VERSION "ADD"

NS_ :

BS_:

BU_: ADD

BO_ 379 ADD_ChassisFusion_0x17B: 16 ADD
 SG_ ADDKeepAwakeReq : 39|1@0+ (1,0) [0|1] "" Vector__XXX
 SG_ ParkGearReqEnaFrmADD : 20|2@0+ (1,0) [0|3] "" Vector__XXX
 SG_ ParkGearReqFrmADD : 18|3@0+ (1,0) [0|7] "" Vector__XXX
 SG_ ParkGearReqSigGrpChks : 7|8@0+ (1,0) [0|255] "" Vector__XXX
 SG_ ParkGearReqSigGrpCntr : 11|4@0+ (1,0) [0|15] "" Vector__XXX
 SG_ ParkGearReqSigGrpFV : 87|16@0+ (1,0) [0|65535] "" Vector__XXX
 SG_ ParkGearReqSigGrpMAC : 103|32@0+ (1,0) [0|0] "" Vector__XXX
 SG_ RPAHVOnReqFrmADD : 21|1@0+ (1,0) [0|1] "" Vector__XXX
 SG_ RPAPrkinRecdFrmADD : 23|2@0+ (1,0) [0|3] "" Vector__XXX

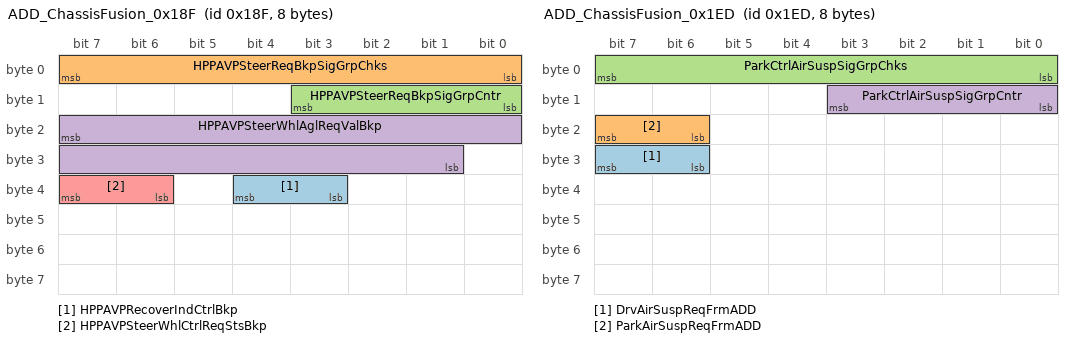
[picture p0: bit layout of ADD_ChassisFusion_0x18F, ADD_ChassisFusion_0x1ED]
BO_ 399 ADD_ChassisFusion_0x18F: 8 ADD
 SG_ HPPAVPRecoverIndCtrlBkp : 36|2@0+ (1,0) [0|3] "" Vector__XXX
 SG_ HPPAVPSteerReqBkpSigGrpChks : 7|8@0+ (1,0) [0|255] "" Vector__XXX
 SG_ HPPAVPSteerReqBkpSigGrpCntr : 11|4@0+ (1,0) [0|15] "" Vector__XXX
 SG_ HPPAVPSteerWhlAglReqValBkp : 23|15@0- (0.0625,0) [-780|780] "deg" Vector__XXX
 SG_ HPPAVPSteerWhlCtrlReqStsBkp : 39|2@0+ (1,0) [0|3] "" Vector__XXX

BO_ 493 ADD_ChassisFusion_0x1ED: 8 ADD
 SG_ DrvAirSuspReqFrmADD : 31|2@0+ (1,0) [0|3] "" Vector__XXX
 SG_ ParkAirSuspReqFrmADD : 23|2@0+ (1,0) [0|3] "" Vector__XXX
 SG_ ParkCtrlAirSuspSigGrpChks : 7|8@0+ (1,0) [0|255] "" Vector__XXX
 SG_ ParkCtrlAirSuspSigGrpCntr : 11|4@0+ (1,0) [0|15] "" Vector__XXX

BO_ 512 ADD_ChassisFusion_0x200: 48 ADD
 SG_ ADDBSDLCAStsFrmADD : 271|2@0+ (1,0) [0|3] "" Vector__XXX
 SG_ ADSAEBStsFrmADD : 279|3@0+ (1,0) [0|7] "" Vector__XXX
 SG_ ADSAEBTarDirFrmADD : 303|3@0+ (1,0) [0|4] "" Vector__XXX
 SG_ ADSAEBWarnReqFrmADD : 37|2@0+ (1,0) [0|3] "" Vector__XXX
 SG_ AdsAutoTurnLiCnclReqFrmADD : 89|2@0+ (1,0) [0|3] "" Vector__XXX
 SG_ AdsAutoTurnLiSwtStsFrmADD : 167|3@0+ (1,0) [0|7] "" Vector__XXX
 SG_ AdsAutoTurnLiUnavlRsnFrmADD : 164|4@0+ (1,0) [0|15] "" Vector__XXX
 SG_ ADSBSDLCAAudioWarnReqFrmADD : 79|2@0+ (1,0) [0|2] "" Vector__XXX
 SG_ ADSBSDLCAWarnReqLeFrmADD : 35|2@0+ (1,0) [0|3] "" Vector__XXX
 SG_ ADSBSDLCAWarnReqRiFrmADD : 47|2@0+ (1,0) [0|3] "" Vector__XXX
 SG_ ADSBSDLightWarningLeReqFrmADD : 77|2@0+ (1,0) [0|2] "" Vector__XXX
 SG_ ADSBSDLightWarningRiReqFrmADD : 75|2@0+ (1,0) [0|2] "" Vector__XXX
 SG_ ADSDOWStsFrmADD : 269|2@0+ (1,0) [0|3] "" Vector__XXX
 SG_ ADSDOWWarnReqFrLeFrmADD : 45|2@0+ (1,0) [0|3] "" Vector__XXX
 SG_ ADSDOWWarnReqFrRiFrmADD : 15|2@0+ (1,0) [0|3] "" Vector__XXX
 SG_ ADSDOWWarnReqReLeFrmADD : 13|2@0+ (1,0) [0|3] "" Vector__XXX
 SG_ ADSDOWWarnReqReRiFrmADD : 43|2@0+ (1,0) [0|3] "" Vector__XXX
 SG_ ADSELKStsFrmADD : 276|3@0+ (1,0) [0|7] "" Vector__XXX
 SG_ ADSESSStsFrmADD : 287|3@0+ (1,0) [0|7] "" Vector__XXX
 SG_ ADSESSWarnReqFrmADD : 41|1@0+ (1,0) [0|1] "" Vector__XXX
 SG_ ADSFctStsSigGrpChks : 263|8@0+ (1,0) [0|255] "" Vector__XXX
 SG_ ADSFctStsSigGrpCntr : 267|4@0+ (1,0) [0|15] "" Vector__XXX
 SG_ ADSFCWReqFrmADD : 23|2@0+ (1,0) [0|3] "" Vector__XXX
 SG_ ADSFCWStsFrmADD : 284|3@0+ (1,0) [0|7] "" Vector__XXX
 SG_ ADSGearReqSigGrpChks : 175|8@0+ (1,0) [0|255] "" Vector__XXX
 SG_ ADSGearReqSigGrpCntr : 179|4@0+ (1,0) [0|15] "" Vector__XXX
 SG_ AdsIntelgntSpdSwtStsFrmADD : 159|3@0+ (1,0) [0|7] "" Vector__XXX
 SG_ AdsIntelgntSpdUnavlRsnFrmADD : 156|3@0+ (1,0) [0|7] "" Vector__XXX
 SG_ ADSLDPHandOffExitFrmADD : 56|1@0+ (1,0) [0|1] "" Vector__XXX
 SG_ ADSLDPHandOffWarningFrmADD : 65|2@0+ (1,0) [0|3] "" Vector__XXX
 SG_ ADSLDPStsFrmADD : 295|3@0+ (1,0) [0|7] "" Vector__XXX
 SG_ ADSLDPWarnReqLeFrmADD : 21|1@0+ (1,0) [0|1] "" Vector__XXX
 SG_ ADSLDPWarnReqRiFrmADD : 20|1@0+ (1,0) [0|1] "" Vector__XXX
 SG_ ADSLDWStsFrmADD : 292|3@0+ (1,0) [0|7] "" Vector__XXX
 SG_ ADSLDWWarnLeReqFrmADD : 19|1@0+ (1,0) [0|1] "" Vector__XXX
 SG_ ADSLDWWarnRiReqFrmADD : 18|1@0+ (1,0) [0|1] "" Vector__XXX
 SG_ AdsLearnSwtStsFrmADD : 370|3@0+ (1,0) [0|7] "" Vector__XXX
 SG_ AdsLearnSwtUnavlRsnFrmADD : 363|4@0+ (1,0) [0|15] "" Vector__XXX
 SG_ ADSLiReqFrmADD : 142|2@0+ (1,0) [0|3] "" Vector__XXX
 SG_ ADSMAIInhibitReqFrmADD : 207|2@0+ (1,0) [0|3] "" Vector__XXX
 SG_ ADSMAIStsFrmADD : 205|3@0+ (1,0) [0|7] "" Vector__XXX
 SG_ ADSMAIWarnReqFrmADD : 202|2@0+ (1,0) [0|3] "" Vector__XXX
 SG_ AdsModSwtStsFrmADD : 367|4@0+ (1,0) [0|15] "" Vector__XXX
 SG_ AdsNOAOddSwtStsFrmADD : 355|4@0+ (1,0) [0|15] "" Vector__XXX
 SG_ AdsNOAOddSwtUnavlRsnFrmADD : 373|3@0+ (1,0) [0|7] "" Vector__XXX
 SG_ ADSRCTAStsFrmADD : 273|2@0+ (1,0) [0|3] "" Vector__XXX
 SG_ ADSRCTAWarnReqLeFrmADD : 17|2@0+ (1,0) [0|3] "" Vector__XXX
 SG_ ADSRCTAWarnReqRiFrmADD : 31|2@0+ (1,0) [0|3] "" Vector__XXX
 SG_ ADSRCTBStsFrmADD : 281|2@0+ (1,0) [0|3] "" Vector__XXX
 SG_ ADSRCTBWarnReqLeFrmADD : 29|2@0+ (1,0) [0|3] "" Vector__XXX
 SG_ ADSRCTBWarnReqRiFrmADD : 27|2@0+ (1,0) [0|3] "" Vector__XXX
 SG_ ADSRCWStsFrmADD : 289|2@0+ (1,0) [0|3] "" Vector__XXX
 SG_ ADSRCWWarnReqFrmADD : 25|2@0+ (1,0) [0|3] "" Vector__XXX
 SG_ ADSSysErrorRmdFrmADD : 95|2@0+ (1,0) [0|3] "" Vector__XXX
 SG_ ADSSysErrorStsFrmADD : 93|2@0+ (1,0) [0|3] "" Vector__XXX
 SG_ ADSTakeoverRmdFrmADD : 91|2@0+ (1,0) [0|3] "" Vector__XXX
 SG_ ADSTLAStsFrmADD : 335|3@0+ (1,0) [0|7] "" Vector__XXX
 SG_ AdsTrfcLiCtrlSwtStsFrmADD : 375|2@0+ (1,0) [0|3] "" Vector__XXX
 SG_ ADSVcCtrlArbFrmADD : 39|2@0+ (1,0) [0|3] "" Vector__XXX
 SG_ AdsVehDetourSwtStsFrmADD : 357|2@0+ (1,0) [0|3] "" Vector__XXX
 SG_ ADSWarnSigGrpChks : 7|8@0+ (1,0) [0|255] "" Vector__XXX
 SG_ ADSWarnSigGrpCntr : 11|4@0+ (1,0) [0|15] "" Vector__XXX
 SG_ ADSwtStsSigGrp2Chks : 343|8@0+ (1,0) [0|255] "" Vector__XXX
 SG_ ADSwtStsSigGrp2Cntr : 347|4@0+ (1,0) [0|15] "" Vector__XXX
 SG_ AEBTarObjClassFrmADD : 223|2@0+ (1,0) [0|3] "" Vector__XXX
 SG_ AEBTarObjTTIFrmADD : 231|8@0+ (0.02,0) [0|5.1] "" Vector__XXX
 SG_ AEBtoIDPFrmADDChks : 215|8@0+ (1,0) [0|255] "" Vector__XXX
 SG_ AEBtoIDPFrmADDCntr : 219|4@0+ (1,0) [0|15] "" Vector__XXX
 SG_ AutoDrvLaneChgStsFrmADD : 103|4@0+ (1,0) [0|15] "" Vector__XXX
 SG_ AVMCamVideoChainSts : 245|2@0+ (1,0) [0|3] "" Vector__XXX
 SG_ AVMCamVideoChainStsChks : 239|8@0+ (1,0) [0|255] "" Vector__XXX
 SG_ AVMCamVideoChainStsCntr : 243|4@0+ (1,0) [0|15] "" Vector__XXX
 SG_ DrvAtmLiReqFrmADD : 40|1@0+ (1,0) [0|1] "" Vector__XXX
 SG_ DrvGearReqFrmADD : 191|3@0+ (1,0) [0|7] "" Vector__XXX
 SG_ DrvGearReqVldFrmADD : 188|1@0+ (1,0) [0|1] "" Vector__XXX
 SG_ DrvHUDDspFrmADD : 99|4@0+ (1,0) [0|15] "" Vector__XXX
 SG_ DrvLaneChgStsFrmADD : 111|4@0+ (1,0) [0|15] "" Vector__XXX
 SG_ DrvMdlStsFrmADD : 317|3@0+ (1,0) [0|7] "" Vector__XXX
 SG_ DrvNOAExtLgtDstFrmADD : 119|9@0+ (1,0) [0|511] "m" Vector__XXX
 SG_ DrvNOAQutLgtDstFrmADD : 135|9@0+ (1,0) [0|511] "m" Vector__XXX
 SG_ DrvNOARemdFrmADD : 327|6@0+ (1,0) [0|63] "" Vector__XXX
 SG_ DrvPltSysStsFrmADD : 126|4@0+ (1,0) [0|15] "" Vector__XXX
 SG_ DrvPnt2PntExtLgtDstFrmADD : 311|9@0+ (1,0) [0|511] "m" Vector__XXX
 SG_ DrvPnt2PntSysStsFrmADD : 332|5@0+ (1,0) [0|31] "" Vector__XXX
 SG_ DrvrSeldDstLvlFrmADD : 122|3@0+ (1,0) [0|7] "" Vector__XXX
 SG_ DrvSysWarnFrmADD : 55|3@0+ (1,0) [0|7] "" Vector__XXX
 SG_ DrvTurnLiReqFrmADD : 140|2@0+ (1,0) [0|3] "" Vector__XXX
 SG_ IndcrCancelReqFrmADD : 138|2@0+ (1,0) [0|3] "" Vector__XXX
 SG_ LidarCleanReqFrmADD : 321|2@0+ (1,0) [0|3] "" Vector__XXX
 SG_ NOASysStsFrmADD : 107|4@0+ (1,0) [0|15] "" Vector__XXX
 SG_ NOATypFrmADD : 153|2@0+ (1,0) [0|3] "-" Vector__XXX
 SG_ TSASignQlyFrmADD : 63|7@0+ (1,0) [0|126] "" Vector__XXX
 SG_ TSASignTypeFrmADD : 71|6@0+ (1,0) [0|63] "" Vector__XXX
 SG_ TSASpdLimitFrmADD : 52|5@0+ (1,0) [0|31] "" Vector__XXX
 SG_ TSASpdLimitUnitFrmADD : 33|2@0+ (1,0) [0|3] "" Vector__XXX
 SG_ UserFbReqFrmADD : 151|2@0+ (1,0) [0|3] "" Vector__XXX

BO_ 513 ADD_ChassisFusion_0x201: 48 ADD
 SG_ ADSAPPUnableOpenRsnFrmADD : 162|3@0+ (1,0) [0|7] "" Vector__XXX
 SG_ ADSAVPStsFrmADD : 127|4@0+ (1,0) [0|15] "" Vector__XXX
 SG_ ADSHPPStsFrmADD : 95|4@0+ (1,0) [0|15] "" Vector__XXX
 SG_ ADSLRRSnsrStsFrmADD : 351|4@0+ (1,0) [0|15] "" Vector__XXX
 SG_ ADSRLSRSnsrStsFrmADD : 71|4@0+ (1,0) [0|15] "" Vector__XXX
 SG_ ADSRRSRSnsrStsFrmADD : 67|4@0+ (1,0) [0|15] "" Vector__XXX
 SG_ AFrCamStsFrmADD : 245|3@0+ (1,0) [0|7] "" Vector__XXX
 SG_ ALeCamStsFrmADD : 250|3@0+ (1,0) [0|7] "" Vector__XXX
 SG_ APAIcnDispStsFrmADD : 335|3@0+ (1,0) [0|7] "" Vector__XXX
 SG_ APAVcFbFrmADD : 231|7@0+ (1,0) [0|127] "" Vector__XXX
 SG_ APAVcQuitAvlFrmADD : 220|1@0+ (1,0) [0|1] "" Vector__XXX
 SG_ APAVcStsFrmADD : 219|1@0+ (1,0) [0|1] "" Vector__XXX
 SG_ AReCamStsFrmADD : 253|3@0+ (1,0) [0|7] "" Vector__XXX
 SG_ ARiCamStsFrmADD : 7|3@0+ (1,0) [0|7] "" Vector__XXX
 SG_ AVMOpnReqFrmADD : 223|3@0+ (1,0) [0|7] "" Vector__XXX
 SG_ AVPHPPStatusSigGrpChks : 87|8@0+ (1,0) [0|255] "" Vector__XXX
 SG_ AVPHPPStatusSigGrpCntr : 91|4@0+ (1,0) [0|15] "" Vector__XXX
 SG_ AVPIcnDispStsFrmADD : 332|3@0+ (1,0) [0|7] "" Vector__XXX
 SG_ CameraStsforADBFrmADD : 279|2@0+ (1,0) [0|3] "" Vector__XXX
 SG_ CameraStsFrmADD : 277|2@0+ (1,0) [0|3] "" Vector__XXX
 SG_ F120CamStsFrmADD : 35|3@0+ (1,0) [0|7] "" Vector__XXX
 SG_ F120DVRStsFrmADD : 15|3@0+ (1,0) [0|7] "" Vector__XXX
 SG_ F30CamStsFrmADD : 4|3@0+ (1,0) [0|7] "" Vector__XXX
 SG_ F30DVRStsFrmADD : 12|3@0+ (1,0) [0|7] "" Vector__XXX
 SG_ FLidarStsFrmADD : 47|4@0+ (1,0) [0|15] "" Vector__XXX
 SG_ FUSSStsFrmADD : 43|4@0+ (1,0) [0|15] "" Vector__XXX
 SG_ HPPActiveSubStsFrmADD : 114|3@0+ (1,0) [0|7] "" Vector__XXX
 SG_ HPPAlrtWarnFrmADD : 151|3@0+ (1,0) [0|7] "" Vector__XXX
 SG_ HPPAVPModSts : 76|3@0+ (1,0) [0|7] "" Vector__XXX
 SG_ HPPBakMapDfltParkSlotDispFrmADD : 311|1@0+ (1,0) [0|1] "" Vector__XXX
 SG_ HPPDriverOperateDialogFrmADD : 111|4@0+ (1,0) [0|15] "" Vector__XXX
 SG_ HPPDriverOperateInd2FrmADD : 119|5@0+ (1,0) [0|31] "" Vector__XXX
 SG_ HPPDriverOperateIndFrmADD : 143|5@0+ (1,0) [0|31] "" Vector__XXX
 SG_ HPPIcnDispStsFrmADD : 343|3@0+ (1,0) [0|7] "" Vector__XXX
 SG_ HPPInfotipFrmADD : 103|6@0+ (1,0) [0|63] "" Vector__XXX
 SG_ HPPLearnSubStsFrmADD : 123|4@0+ (1,0) [0|15] "" Vector__XXX
 SG_ HPPLrnVcFbFrmADD : 218|1@0+ (1,0) [0|1] "" Vector__XXX
 SG_ HPPPlayBackPushFrmADD : 310|1@0+ (1,0) [0|1] "" Vector__XXX
 SG_ HPPQuitIndFrmADD : 159|7@0+ (1,0) [0|127] "" Vector__XXX
 SG_ HPPRecoverButtonStsFrmADD : 307|2@0+ (1,0) [0|3] "" Vector__XXX
 SG_ HPPRecoverIndFrmADD : 167|5@0+ (1,0) [0|31] "" Vector__XXX
 SG_ HPPRouteInd2FrmADD : 107|4@0+ (1,0) [0|15] "" Vector__XXX
 SG_ HPPRouteIndFrmADD : 148|5@0+ (1,0) [0|31] "" Vector__XXX
 SG_ HPPRouteManageStsFrmADD : 309|1@0+ (1,0) [0|1] "" Vector__XXX
 SG_ HPPToSRSigGrpChks : 295|8@0+ (1,0) [0|255] "" Vector__XXX
 SG_ HPPToSRSigGrpCntr : 299|4@0+ (1,0) [0|15] "" Vector__XXX
 SG_ HPPUnableToActiveIndFrmADD : 135|7@0+ (1,0) [0|127] "" Vector__XXX
 SG_ HPPVehInParkSlotFrmADD : 308|1@0+ (1,0) [0|1] "" Vector__XXX
 SG_ IMUStsFrmADD : 55|4@0+ (1,0) [0|15] "" Vector__XXX
 SG_ ISPLigtSnsrVFrmADD : 263|16@0+ (1,0) [0|65535] "Lux" Vector__XXX
 SG_ LidarStsFrmADD : 275|2@0+ (1,0) [0|3] "" Vector__XXX
 SG_ ParkIcnStsSigGrpChks : 319|8@0+ (1,0) [0|255] "" Vector__XXX
 SG_ ParkIcnStsSigGrpCntr : 323|4@0+ (1,0) [0|15] "" Vector__XXX
 SG_ ParkVCstatusSigGrpChks : 207|8@0+ (1,0) [0|255] "" Vector__XXX
 SG_ ParkVCstatusSigGrpCntr : 211|4@0+ (1,0) [0|15] "" Vector__XXX
 SG_ ParkVicShdFrmADD : 215|3@0+ (1,0) [0|7] "" Vector__XXX
 SG_ PrkSteerWhlBtnLi : 329|2@0+ (1,0) [0|3] "" Vector__XXX
 SG_ ReCamStsFrmADD : 287|3@0+ (1,0) [0|7] "" Vector__XXX
 SG_ ReDVRStsFrmADD : 39|3@0+ (1,0) [0|7] "" Vector__XXX
 SG_ RUSSStsFrmADD : 51|4@0+ (1,0) [0|15] "" Vector__XXX
 SG_ SLFCamStsFrmADD : 234|3@0+ (1,0) [0|7] "" Vector__XXX
 SG_ SLFDVRStsFrmADD : 23|3@0+ (1,0) [0|7] "" Vector__XXX
 SG_ SLLidarStsFrmADD : 63|4@0+ (1,0) [0|15] "" Vector__XXX
 SG_ SLRCamStsFrmADD : 237|3@0+ (1,0) [0|7] "" Vector__XXX
 SG_ SLRDVRStsFrmADD : 20|3@0+ (1,0) [0|7] "" Vector__XXX
 SG_ SnmDetInfoFrmADD : 175|16@0+ (1,0) [0|65535] "" Vector__XXX
 SG_ SnmDetResFrmADD : 185|2@0+ (1,0) [0|3] "" Vector__XXX
 SG_ SnmF120CamDetResFrmADD : 187|2@0+ (1,0) [0|3] "" Vector__XXX
 SG_ SnmReCamDetResFrmADD : 189|2@0+ (1,0) [0|3] "" Vector__XXX
 SG_ SnmSLFCamDetResFrmADD : 191|2@0+ (1,0) [0|3] "" Vector__XXX
 SG_ SnmSLRCamDetResFrmADD : 193|2@0+ (1,0) [0|3] "" Vector__XXX
 SG_ SnmSRFCamDetResFrmADD : 195|2@0+ (1,0) [0|3] "" Vector__XXX
 SG_ SnmSRRCamDetResFrmADD : 197|2@0+ (1,0) [0|3] "" Vector__XXX
 SG_ SRFCamStsFrmADD : 242|3@0+ (1,0) [0|7] "" Vector__XXX
 SG_ SRFDVRStsFrmADD : 31|3@0+ (1,0) [0|7] "" Vector__XXX
 SG_ SRLidarStsFrmADD : 59|4@0+ (1,0) [0|15] "" Vector__XXX
 SG_ SRRCamStsFrmADD : 79|3@0+ (1,0) [0|7] "" Vector__XXX
 SG_ SRRDVRStsFrmADD : 28|3@0+ (1,0) [0|7] "" Vector__XXX

BO_ 516 ADD_ChassisFusion_0x204: 32 ADD
 SG_ APAAlrtWarnFrmADD : 121|2@0+ (1,0) [0|3] "" Vector__XXX
 SG_ APAButtonReqFrmADD : 199|2@0+ (1,0) [0|3] "" Vector__XXX
 SG_ APARPAActiveSubFunFrmADD : 114|3@0+ (1,0) [0|7] "" Vector__XXX
 SG_ APARPADriverOperateInd2FrmADD : 159|6@0+ (1,0) [0|63] "" Vector__XXX
 SG_ APARPADriverOperateIndFrmADD : 127|6@0+ (1,0) [0|63] "" Vector__XXX
 SG_ APARPAQuitReasonIndFrmADD : 135|6@0+ (1,0) [0|63] "" Vector__XXX
 SG_ APARPARecoverIndFrmADD : 143|5@0+ (1,0) [0|31] "" Vector__XXX
 SG_ APARPAstatusFrmADD : 118|4@0+ (1,0) [0|15] "" Vector__XXX
 SG_ APARPAstatusSigGrpChks : 87|8@0+ (1,0) [0|255] "" Vector__XXX
 SG_ APARPAstatusSigGrpCntr : 91|4@0+ (1,0) [0|15] "" Vector__XXX
 SG_ APARPAUnableToActiveIndFrmADD : 151|6@0+ (1,0) [0|63] "" Vector__XXX
 SG_ AVPCharLidCtrlFrmADD : 15|2@0+ (1,0) [0|3] "" Vector__XXX
 SG_ DriverlessStsFrmADD : 185|2@0+ (1,0) [0|3] "" Vector__XXX
 SG_ OutdoorPrkDrvrOperIndFrmADD : 197|6@0+ (1,0) [0|63] "" Vector__XXX
 SG_ OutdoorPrkQuitIndFrmADD : 191|6@0+ (1,0) [0|63] "" Vector__XXX
 SG_ OutdoorPrkRecoverIndFrmADD : 183|5@0+ (1,0) [0|31] "" Vector__XXX
 SG_ OutdoorPrkUnableToActvIndFrmADD : 175|6@0+ (1,0) [0|63] "" Vector__XXX
 SG_ ParkActiveRearSpoilerReqFrmADD : 202|3@0+ (1,0) [0|7] "" Vector__XXX
 SG_ ParkAtmLiReqFrmADD : 13|2@0+ (1,0) [0|3] "" Vector__XXX
 SG_ ParkBackMirrorUnfoldReqFrmADD : 23|2@0+ (1,0) [0|3] "" Vector__XXX
 SG_ ParkCornrLiReqFrmADD : 207|2@0+ (1,0) [0|3] "" Vector__XXX
 SG_ ParkDoorLockReqFrmADD : 21|2@0+ (1,0) [0|3] "" Vector__XXX
 SG_ ParkingPushFrmADD : 71|3@0+ (1,0) [0|7] "" Vector__XXX
 SG_ ParkLightReqSigGrpChks : 7|8@0+ (1,0) [0|255] "" Vector__XXX
 SG_ ParkLightReqSigGrpCntr : 11|4@0+ (1,0) [0|15] "" Vector__XXX
 SG_ ParkLoBeamReqFrmADD : 19|1@0+ (1,0) [0|1] "" Vector__XXX
 SG_ ParkMdlStsFrmADD : 63|3@0+ (1,0) [0|7] "" Vector__XXX
 SG_ ParkProgressSigReDistFrmADD : 111|9@0+ (1,0) [0|511] "dm" Vector__XXX
 SG_ ParkTurnLiReqFrmADD : 18|2@0+ (1,0) [0|3] "" Vector__XXX
 SG_ ParkWindowReqFrmADD : 16|1@0+ (1,0) [0|1] "" Vector__XXX
 SG_ PASBuzzerWarnMuteIndFrmADD : 57|1@0+ (1,0) [0|1] "" Vector__XXX
 SG_ PRAMoveSigReDistFrmADD : 103|8@0+ (1,0) [0|255] "dm" Vector__XXX
 SG_ PrkgHornReqFrmADD : 31|1@0+ (1,0) [0|1] "" Vector__XXX
 SG_ RPAAvailableFrmADD : 30|1@0+ (1,0) [0|1] "" Vector__XXX
 SG_ RPAAvailableFrmADDFV : 215|16@0+ (1,0) [0|65535] "" Vector__XXX
 SG_ RPAAvailableFrmADDMAC : 231|32@0+ (1,0) [0|0] "" Vector__XXX
 SG_ RPADriverOperateIndFrmADD : 79|4@0+ (1,0) [0|15] "" Vector__XXX
 SG_ RPAOperateToastFrmADD : 75|4@0+ (1,0) [0|15] "" Vector__XXX
 SG_ RPAQuitReasonIndFrmADD : 55|7@0+ (1,0) [0|127] "" Vector__XXX
 SG_ RPARecoverIndFrmADD : 68|5@0+ (1,0) [0|31] "" Vector__XXX
 SG_ RPAUnableToActiveIndFrmADD : 47|4@0+ (1,0) [0|15] "" Vector__XXX
 SG_ WeatherStsFrmADD : 60|3@0+ (1,0) [0|7] "" Vector__XXX

BO_ 518 ADD_ChassisFusion_0x206: 64 ADD
 SG_ BndryLeftAng1FrmADD : 263|13@0- (0.01,0) [-40.96|40.95] "" Vector__XXX
 SG_ BndryLeftAng2FrmADD : 287|13@0- (0.01,0) [-40.96|40.95] "" Vector__XXX
 SG_ BndryLeftAng3FrmADD : 311|13@0- (0.01,0) [-40.96|40.95] "" Vector__XXX
 SG_ BndryLeftAng4FrmADD : 335|13@0- (0.01,0) [-40.96|40.95] "" Vector__XXX
 SG_ BndryLeftAng5FrmADD : 359|13@0- (0.01,0) [-40.96|40.95] "" Vector__XXX
 SG_ BndryLeftDist1FrmADD : 265|10@0+ (1,0) [0|1023] "" Vector__XXX
 SG_ BndryLeftDist2FrmADD : 289|10@0+ (1,0) [0|1023] "" Vector__XXX
 SG_ BndryLeftDist3FrmADD : 313|10@0+ (1,0) [0|1023] "" Vector__XXX
 SG_ BndryLeftDist4FrmADD : 337|10@0+ (1,0) [0|1023] "" Vector__XXX
 SG_ BndryLeftDist5FrmADD : 361|10@0+ (1,0) [0|1023] "" Vector__XXX
 SG_ BndryLowerAng1FrmADD : 383|13@0- (0.01,0) [-40.96|40.95] "" Vector__XXX
 SG_ BndryLowerAng2FrmADD : 407|13@0- (0.01,0) [-40.96|40.95] "" Vector__XXX
 SG_ BndryLowerAng3FrmADD : 431|13@0- (0.01,0) [-40.96|40.95] "" Vector__XXX
 SG_ BndryLowerAng4FrmADD : 455|13@0- (0.01,0) [-40.96|40.95] "" Vector__XXX
 SG_ BndryLowerAng5FrmADD : 479|13@0- (0.01,0) [-40.96|40.95] "" Vector__XXX
 SG_ BndryLowerDist1FrmADD : 385|10@0+ (1,0) [0|1023] "" Vector__XXX
 SG_ BndryLowerDist2FrmADD : 409|10@0+ (1,0) [0|1023] "" Vector__XXX
 SG_ BndryLowerDist3FrmADD : 433|10@0+ (1,0) [0|1023] "" Vector__XXX
 SG_ BndryLowerDist4FrmADD : 457|10@0+ (1,0) [0|1023] "" Vector__XXX
 SG_ BndryLowerDist5FrmADD : 481|10@0+ (1,0) [0|1023] "" Vector__XXX
 SG_ VehObjDist1FrmADD : 7|10@0+ (1,0) [0|1023] "m" Vector__XXX
 SG_ VehObjDist2FrmADD : 9|10@0+ (1,0) [0|1023] "m" Vector__XXX
 SG_ VehObjDist3FrmADD : 31|10@0+ (1,0) [0|1023] "m" Vector__XXX
 SG_ VehObjDist4FrmADD : 33|10@0+ (1,0) [0|1023] "m" Vector__XXX
 SG_ VehObjDist5FrmADD : 55|10@0+ (1,0) [0|1023] "m" Vector__XXX
 SG_ VehObjDist6FrmADD : 57|10@0+ (1,0) [0|1023] "m" Vector__XXX
 SG_ VehObjDist7FrmADD : 79|10@0+ (1,0) [0|1023] "m" Vector__XXX
 SG_ VehObjDist8FrmADD : 81|10@0+ (1,0) [0|1023] "m" Vector__XXX
 SG_ VehObjHorzCtrAng1FrmADD : 103|11@0- (0.05,0) [-51.2|51.15] "Deg" Vector__XXX
 SG_ VehObjHorzCtrAng2FrmADD : 106|11@0- (0.05,0) [-51.2|51.15] "Deg" Vector__XXX
 SG_ VehObjHorzCtrAng3FrmADD : 127|11@0- (0.05,0) [-51.2|51.15] "Deg" Vector__XXX
 SG_ VehObjHorzCtrAng4FrmADD : 130|11@0- (0.05,0) [-51.2|51.15] "Deg" Vector__XXX
 SG_ VehObjHorzCtrAng5FrmADD : 151|11@0- (0.05,0) [-51.2|51.15] "Deg" Vector__XXX
 SG_ VehObjHorzCtrAng6FrmADD : 154|11@0- (0.05,0) [-51.2|51.15] "Deg" Vector__XXX
 SG_ VehObjHorzCtrAng7FrmADD : 175|11@0- (0.05,0) [-51.2|51.15] "Deg" Vector__XXX
 SG_ VehObjHorzCtrAng8FrmADD : 178|11@0- (0.05,0) [-51.2|51.15] "Deg" Vector__XXX
 SG_ VehObjHorzWidthAng1FrmADD : 199|7@0+ (0.1,0) [0|12.7] "m" Vector__XXX
 SG_ VehObjHorzWidthAng2FrmADD : 207|7@0+ (0.1,0) [0|12.7] "m" Vector__XXX
 SG_ VehObjHorzWidthAng3FrmADD : 215|7@0+ (0.1,0) [0|12.7] "m" Vector__XXX
 SG_ VehObjHorzWidthAng4FrmADD : 223|7@0+ (0.1,0) [0|12.7] "m" Vector__XXX
 SG_ VehObjHorzWidthAng5FrmADD : 231|7@0+ (0.1,0) [0|12.7] "m" Vector__XXX
 SG_ VehObjHorzWidthAng6FrmADD : 247|7@0+ (0.1,0) [0|12.7] "m" Vector__XXX
 SG_ VehObjHorzWidthAng7FrmADD : 239|7@0+ (0.1,0) [0|12.7] "m" Vector__XXX
 SG_ VehObjHorzWidthAng8FrmADD : 255|7@0+ (0.1,0) [0|12.7] "m" Vector__XXX

BO_ 519 ADD_ChassisFusion_0x207: 64 ADD
 SG_ BndryRightAng1FrmADD : 7|13@0- (0.01,0) [-40.96|40.95] "" Vector__XXX
 SG_ BndryRightAng2FrmADD : 31|13@0- (0.01,0) [-40.96|40.95] "" Vector__XXX
 SG_ BndryRightAng3FrmADD : 55|13@0- (0.01,0) [-40.96|40.95] "" Vector__XXX
 SG_ BndryRightAng4FrmADD : 79|13@0- (0.01,0) [-40.96|40.95] "" Vector__XXX
 SG_ BndryRightAng5FrmADD : 103|13@0- (0.01,0) [-40.96|40.95] "" Vector__XXX
 SG_ BndryRightDist1FrmADD : 9|10@0+ (1,0) [0|1023] "" Vector__XXX
 SG_ BndryRightDist2FrmADD : 33|10@0+ (1,0) [0|1023] "" Vector__XXX
 SG_ BndryRightDist3FrmADD : 57|10@0+ (1,0) [0|1023] "" Vector__XXX
 SG_ BndryRightDist4FrmADD : 81|10@0+ (1,0) [0|1023] "" Vector__XXX
 SG_ BndryRightDist5FrmADD : 105|10@0+ (1,0) [0|1023] "" Vector__XXX
 SG_ BndryValidity1FrmADD : 10|1@0+ (1,0) [0|1] "" Vector__XXX
 SG_ BndryValidity2FrmADD : 34|1@0+ (1,0) [0|1] "" Vector__XXX
 SG_ BndryValidity3FrmADD : 58|1@0+ (1,0) [0|1] "" Vector__XXX
 SG_ BndryValidity4FrmADD : 82|1@0+ (1,0) [0|1] "" Vector__XXX
 SG_ BndryValidity5FrmADD : 106|1@0+ (1,0) [0|1] "" Vector__XXX
 SG_ EnvIllumFrmADD : 258|2@0+ (1,0) [0|3] "" Vector__XXX
 SG_ RoadCondDistFrmADD : 376|9@0+ (1,0) [0|500] "" Vector__XXX
 SG_ RoadConditionFrmADD : 399|8@0+ (1,0) [0|100] "" Vector__XXX
 SG_ RoadCondLenthFrmADD : 415|9@0+ (1,0) [0|500] "" Vector__XXX
 SG_ TooManyBndryFlagFrmADD : 133|1@0+ (1,0) [0|1] "" Vector__XXX
 SG_ TooManyVehFlagFrmADD : 132|1@0+ (1,0) [0|1] "" Vector__XXX
 SG_ TrafSignDist1FrmADD : 127|10@0+ (1,0) [0|1023] "m" Vector__XXX
 SG_ TrafSignDist2FrmADD : 143|10@0+ (1,0) [0|1023] "m" Vector__XXX
 SG_ TrafSignHorzCtrAng1FrmADD : 159|11@0- (0.05,0) [-51.2|51.15] "Deg" Vector__XXX
 SG_ TrafSignHorzCtrAng2FrmADD : 255|11@0- (0.05,0) [-51.2|51.15] "Deg" Vector__XXX
 SG_ TrafSignHorzWidthAng1FrmADD : 350|7@0+ (0.1,0) [0|12.7] "Deg" Vector__XXX
 SG_ TrafSignHorzWidthAng2FrmADD : 383|7@0+ (0.1,0) [0|12.7] "Deg" Vector__XXX
 SG_ TrafSignID1FrmADD : 359|10@0+ (1,0) [0|1023] "" Vector__XXX
 SG_ TrafSignID2FrmADD : 361|10@0+ (1,0) [0|1023] "" Vector__XXX
 SG_ TrafSignValidity1FrmADD : 131|1@0+ (1,0) [0|1] "" Vector__XXX
 SG_ TrafSignValidity2FrmADD : 130|1@0+ (1,0) [0|1] "" Vector__XXX
 SG_ VehObjDir1FrmADD : 129|1@0+ (1,0) [0|1] "" Vector__XXX
 SG_ VehObjDir2FrmADD : 128|1@0+ (1,0) [0|1] "" Vector__XXX
 SG_ VehObjDir3FrmADD : 149|1@0+ (1,0) [0|1] "" Vector__XXX
 SG_ VehObjDir4FrmADD : 148|1@0+ (1,0) [0|1] "" Vector__XXX
 SG_ VehObjDir5FrmADD : 147|1@0+ (1,0) [0|1] "" Vector__XXX
 SG_ VehObjDir6FrmADD : 146|1@0+ (1,0) [0|1] "" Vector__XXX
 SG_ VehObjDir7FrmADD : 145|1@0+ (1,0) [0|1] "" Vector__XXX
 SG_ VehObjDir8FrmADD : 144|1@0+ (1,0) [0|1] "" Vector__XXX
 SG_ VehObjID1FrmADD : 175|16@0+ (1,0) [0|65535] "" Vector__XXX
 SG_ VehObjID2FrmADD : 191|16@0+ (1,0) [0|65535] "" Vector__XXX
 SG_ VehObjID3FrmADD : 207|16@0+ (1,0) [0|65535] "" Vector__XXX
 SG_ VehObjID4FrmADD : 223|16@0+ (1,0) [0|65535] "" Vector__XXX
 SG_ VehObjID5FrmADD : 239|16@0+ (1,0) [0|65535] "" Vector__XXX
 SG_ VehObjID6FrmADD : 271|16@0+ (1,0) [0|65535] "" Vector__XXX
 SG_ VehObjID7FrmADD : 287|16@0+ (1,0) [0|65535] "" Vector__XXX
 SG_ VehObjID8FrmADD : 303|16@0+ (1,0) [0|65535] "" Vector__XXX
 SG_ VehObjType1FrmADD : 319|4@0+ (1,0) [0|15] "" Vector__XXX
 SG_ VehObjType2FrmADD : 315|4@0+ (1,0) [0|15] "" Vector__XXX
 SG_ VehObjType3FrmADD : 327|4@0+ (1,0) [0|15] "" Vector__XXX
 SG_ VehObjType4FrmADD : 323|4@0+ (1,0) [0|15] "" Vector__XXX
 SG_ VehObjType5FrmADD : 335|4@0+ (1,0) [0|15] "" Vector__XXX
 SG_ VehObjType6FrmADD : 331|4@0+ (1,0) [0|15] "" Vector__XXX
 SG_ VehObjType7FrmADD : 343|4@0+ (1,0) [0|15] "" Vector__XXX
 SG_ VehObjType8FrmADD : 339|4@0+ (1,0) [0|15] "" Vector__XXX
 SG_ VehObjValidity1FrmADD : 164|1@0+ (1,0) [0|1] "" Vector__XXX
 SG_ VehObjValidity2FrmADD : 163|1@0+ (1,0) [0|1] "" Vector__XXX
 SG_ VehObjValidity3FrmADD : 162|1@0+ (1,0) [0|1] "" Vector__XXX
 SG_ VehObjValidity4FrmADD : 161|1@0+ (1,0) [0|1] "" Vector__XXX
 SG_ VehObjValidity5FrmADD : 160|1@0+ (1,0) [0|1] "" Vector__XXX
 SG_ VehObjValidity6FrmADD : 260|1@0+ (1,0) [0|1] "" Vector__XXX
 SG_ VehObjValidity7FrmADD : 259|1@0+ (1,0) [0|1] "" Vector__XXX
 SG_ VehObjValidity8FrmADD : 351|1@0+ (1,0) [0|1] "" Vector__XXX

BO_ 528 ADD_ChassisFusion_0x210: 8 ADD
 SG_ ADDSyncFVReq : 7|32@0+ (1,0) [0|4294967295] "" Vector__XXX

BO_ 661 ADD_ChassisFusion_0x295: 32 ADD
 SG_ ADSRCTBBrkReqFrmADD : 31|1@0+ (1,0) [0|1] "" Vector__XXX
 SG_ ADSRCTBBrkSigGrpChks : 7|8@0+ (1,0) [0|255] "" Vector__XXX
 SG_ ADSRCTBBrkSigGrpCntr : 11|4@0+ (1,0) [0|15] "" Vector__XXX
 SG_ ADSRCTBTarDecelFrmADD : 23|8@0+ (0.05,-10) [-10|2.75] "mps2" Vector__XXX
 SG_ BmpTrk1ConfFrmADD : 199|7@0+ (1,0) [0|127] "%" Vector__XXX
 SG_ BmpTrk1HeiFrmADD : 231|16@0+ (0.05,-1638.4) [-1638.4|1638.35] "" Vector__XXX
 SG_ BmpTrk1TypFrmADD : 207|5@0+ (1,0) [0|31] "" Vector__XXX
 SG_ BmpTrk2ConfFrmADD : 183|7@0+ (1,0) [0|127] "" Vector__XXX
 SG_ BmpTrk2HeiFrmADD : 167|16@0+ (0.05,-1638.4) [-1638.4|1638.35] "" Vector__XXX
 SG_ BmpTrk2TypFrmADD : 191|5@0+ (1,0) [0|31] "" Vector__XXX
 SG_ Road1EndPotXRiFrmADD : 39|16@0+ (0.1,-3276.8) [-3276.8|3276.7] "" Vector__XXX
 SG_ Road1EndPotYRiFrmADD : 103|16@0+ (0.1,-3276.8) [-3276.8|3276.7] "" Vector__XXX
 SG_ Road1StrtPotXLeFrmADD : 55|16@0+ (0.1,-3276.8) [-3276.8|3276.7] "" Vector__XXX
 SG_ Road1StrtPotYLeFrmADD : 119|16@0+ (0.1,-3276.8) [-3276.8|3276.7] "" Vector__XXX
 SG_ Road2EndPotXRiFrmADD : 71|16@0+ (0.1,-3276.8) [-3276.8|3276.7] "" Vector__XXX
 SG_ Road2EndPotYRiFrmADD : 135|16@0+ (0.1,-3276.8) [-3276.8|3276.7] "" Vector__XXX
 SG_ Road2StrtPotXLeFrmADD : 87|16@0+ (0.1,-3276.8) [-3276.8|3276.7] "" Vector__XXX
 SG_ Road2StrtPotYLeFrmADD : 151|16@0+ (0.1,-3276.8) [-3276.8|3276.7] "" Vector__XXX

CM_ SG_ 379 ADDKeepAwakeReq "请求整车电源状态";
CM_ SG_ 379 ParkGearReqEnaFrmADD "Parking system Gear request Enable";
CM_ SG_ 379 ParkGearReqFrmADD "Parking system Gear request";
CM_ SG_ 379 RPAHVOnReqFrmADD "Request HV ON";
CM_ SG_ 379 RPAPrkinRecdFrmADD "RPA Park in Record
RPA 记录上次是遥控泊入还是人为泊入";
CM_ SG_ 399 HPPAVPRecoverIndCtrlBkp "HPP AVP recovery interrupt indication Backup";
CM_ SG_ 399 HPPAVPSteerWhlAglReqValBkp "HPP AVP  Steering Wheel Angle Request Value Backup";
CM_ SG_ 399 HPPAVPSteerWhlCtrlReqStsBkp "HPP AVP Steering Wheel Control Request Status Backup";
CM_ SG_ 493 DrvAirSuspReqFrmADD "driving air suspension request";
CM_ SG_ 493 ParkAirSuspReqFrmADD "Parking Control Air Suspension Request";
CM_ SG_ 512 ADDBSDLCAStsFrmADD "BSD LCA function status";
CM_ SG_ 512 ADSAEBStsFrmADD "AEB function status";
CM_ SG_ 512 ADSAEBTarDirFrmADD "AEB目标方向显示标志";
CM_ SG_ 512 ADSAEBWarnReqFrmADD "AEB warning request";
CM_ SG_ 512 AdsAutoTurnLiCnclReqFrmADD "Adas Auto Turn Light Cancel Request";
CM_ SG_ 512 AdsAutoTurnLiSwtStsFrmADD "Adas Auto Turn Light switch status";
CM_ SG_ 512 AdsAutoTurnLiUnavlRsnFrmADD "Adas Auto Turn Light switch  unavailable reason";
CM_ SG_ 512 ADSBSDLCAAudioWarnReqFrmADD "用于表征 BSDLCA 声音报警需求";
CM_ SG_ 512 ADSBSDLCAWarnReqLeFrmADD "BSD_LCA warning request";
CM_ SG_ 512 ADSBSDLCAWarnReqRiFrmADD "BSD warning request";
CM_ SG_ 512 ADSBSDLightWarningLeReqFrmADD "智驾对左侧BSD灯的请求信号";
CM_ SG_ 512 ADSBSDLightWarningRiReqFrmADD "智驾对右侧BSD灯的请求信号";
CM_ SG_ 512 ADSDOWStsFrmADD "DOW function status";
CM_ SG_ 512 ADSDOWWarnReqFrLeFrmADD "DOW warning request - front left";
CM_ SG_ 512 ADSDOWWarnReqFrRiFrmADD "DOW warning request - front right";
CM_ SG_ 512 ADSDOWWarnReqReLeFrmADD "DOW warning request - rear left";
CM_ SG_ 512 ADSDOWWarnReqReRiFrmADD "DOW warning request - rear right";
CM_ SG_ 512 ADSELKStsFrmADD "ELK function status";
CM_ SG_ 512 ADSESSStsFrmADD "ESS function status";
CM_ SG_ 512 ADSESSWarnReqFrmADD "ESS warning request";
CM_ SG_ 512 ADSFCWReqFrmADD "FCW request";
CM_ SG_ 512 ADSFCWStsFrmADD "FCW function status";
CM_ SG_ 512 AdsIntelgntSpdSwtStsFrmADD "Adas Intelligent Speed switch status";
CM_ SG_ 512 AdsIntelgntSpdUnavlRsnFrmADD "Adas Intelligent Speed switch  unavailable reason";
CM_ SG_ 512 ADSLDPHandOffExitFrmADD "LDP脱手超时退出";
CM_ SG_ 512 ADSLDPHandOffWarningFrmADD "LDP脱手报警提示";
CM_ SG_ 512 ADSLDPStsFrmADD "LDP function status";
CM_ SG_ 512 ADSLDPWarnReqLeFrmADD "LDP warning request - left";
CM_ SG_ 512 ADSLDPWarnReqRiFrmADD "LDP warning request - right";
CM_ SG_ 512 ADSLDWStsFrmADD "LDW function status";
CM_ SG_ 512 ADSLDWWarnLeReqFrmADD "ADS LDW Warning LEFT Request";
CM_ SG_ 512 ADSLDWWarnRiReqFrmADD "ADS LDW Warning right Request";
CM_ SG_ 512 AdsLearnSwtStsFrmADD "Adas learned switch status";
CM_ SG_ 512 AdsLearnSwtUnavlRsnFrmADD "Adas learned switch unavailable reason";
CM_ SG_ 512 ADSLiReqFrmADD "ADS light request";
CM_ SG_ 512 ADSMAIInhibitReqFrmADD "MAI Inhibit Warning Request";
CM_ SG_ 512 ADSMAIStsFrmADD "MAI Function Status";
CM_ SG_ 512 ADSMAIWarnReqFrmADD "MAI Warning Request";
CM_ SG_ 512 AdsModSwtStsFrmADD "Adas mode switch status";
CM_ SG_ 512 AdsNOAOddSwtStsFrmADD "Adas-NOA odd switch status";
CM_ SG_ 512 AdsNOAOddSwtUnavlRsnFrmADD "Adas-NOA odd switch unavailable reason";
CM_ SG_ 512 ADSRCTAStsFrmADD "RCTA function status";
CM_ SG_ 512 ADSRCTAWarnReqLeFrmADD "RCTA warning request";
CM_ SG_ 512 ADSRCTAWarnReqRiFrmADD "RCTA warning request";
CM_ SG_ 512 ADSRCTBStsFrmADD "RCTB function status";
CM_ SG_ 512 ADSRCTBWarnReqLeFrmADD "RCTB warning request";
CM_ SG_ 512 ADSRCTBWarnReqRiFrmADD "RCTB warning request";
CM_ SG_ 512 ADSRCWStsFrmADD "RCW function status";
CM_ SG_ 512 ADSRCWWarnReqFrmADD "RCW warning rcw_warninguest";
CM_ SG_ 512 ADSSysErrorRmdFrmADD "智驾系统故障提示";
CM_ SG_ 512 ADSSysErrorStsFrmADD "智驾系统故障状态";
CM_ SG_ 512 ADSTakeoverRmdFrmADD "智驾紧急请求用户接管";
CM_ SG_ 512 ADSTLAStsFrmADD "TLA功能状态机信号";
CM_ SG_ 512 AdsTrfcLiCtrlSwtStsFrmADD "Adas traffic light control switch status";
CM_ SG_ 512 ADSVcCtrlArbFrmADD "Voice_Control_Arbitration_Feedback";
CM_ SG_ 512 AdsVehDetourSwtStsFrmADD "Adas vehicle detour switch status";
CM_ SG_ 512 AEBTarObjClassFrmADD "AEB target object classification";
CM_ SG_ 512 AEBTarObjTTIFrmADD "AEB  target object time to impact";
CM_ SG_ 512 AutoDrvLaneChgStsFrmADD "Autonomous Lane Change Status";
CM_ SG_ 512 AVMCamVideoChainSts "AVM视频传输链路故障状态";
CM_ SG_ 512 DrvAtmLiReqFrmADD "Atmosphere light request";
CM_ SG_ 512 DrvGearReqFrmADD "Driving Gear request";
CM_ SG_ 512 DrvGearReqVldFrmADD "智驾行车档位请求有效位
0x0 无效
0x1 有效";
CM_ SG_ 512 DrvHUDDspFrmADD "HUD display msg";
CM_ SG_ 512 DrvLaneChgStsFrmADD "Lane Change Status";
CM_ SG_ 512 DrvMdlStsFrmADD "Pilot Driver Model Status";
CM_ SG_ 512 DrvNOAExtLgtDstFrmADD "Noa Exit Longitudinal Relative Distance";
CM_ SG_ 512 DrvNOAQutLgtDstFrmADD "Noa Quit Longitudinal Relative Distance";
CM_ SG_ 512 DrvNOARemdFrmADD "NOA text msg";
CM_ SG_ 512 DrvPltSysStsFrmADD "Pilot System Status
激活状态为 PilotNormalActive PilotOverride_Long PilotOverride_Lat pilotActiveOnlylgt Pilotoverlay StandActive StandWait Takeover MRM";
CM_ SG_ 512 DrvPnt2PntExtLgtDstFrmADD "Point2Point Exit Longitudinal Relative Distance";
CM_ SG_ 512 DrvPnt2PntSysStsFrmADD "Point2Point System Status";
CM_ SG_ 512 DrvrSeldDstLvlFrmADD "Pilot Driver Selected Distance Level";
CM_ SG_ 512 DrvSysWarnFrmADD "Driving system warning request";
CM_ SG_ 512 DrvTurnLiReqFrmADD "ADS turn light request";
CM_ SG_ 512 IndcrCancelReqFrmADD "变道完成后取消长拨杆信号";
CM_ SG_ 512 LidarCleanReqFrmADD "激光雷达清洗请求";
CM_ SG_ 512 NOASysStsFrmADD "NOA System Status
NOA激活状态 NormalActive  NOAOverride_Long StandActive StandWait Overlay  Takeover MRM";
CM_ SG_ 512 NOATypFrmADD "NOA Type";
CM_ SG_ 512 TSASignQlyFrmADD "Quality/Confidence of the detected road sign";
CM_ SG_ 512 TSASignTypeFrmADD "Detected road sign type";
CM_ SG_ 512 TSASpdLimitFrmADD "TSR Traffic Sign Recognition Speed limit values";
CM_ SG_ 512 TSASpdLimitUnitFrmADD "TSR Traffic Sign Recognition  speed limit unit";
CM_ SG_ 512 UserFbReqFrmADD "user feedback request";
CM_ SG_ 513 ADSAPPUnableOpenRsnFrmADD "智驾中心APP无法打开原因提示";
CM_ SG_ 513 ADSAVPStsFrmADD "AVP State Machine Status
AVP 状态机信号";
CM_ SG_ 513 ADSHPPStsFrmADD "HPP State Machine Status
HPP 状态机信号";
CM_ SG_ 513 ADSLRRSnsrStsFrmADD "front radar working status";
CM_ SG_ 513 ADSRLSRSnsrStsFrmADD "rear left radar working status";
CM_ SG_ 513 ADSRRSRSnsrStsFrmADD "rear right radar working status";
CM_ SG_ 513 AFrCamStsFrmADD "AVM Front camera Status";
CM_ SG_ 513 ALeCamStsFrmADD "AVM Left camera Status";
CM_ SG_ 513 APAIcnDispStsFrmADD "APA Icon Display Status
APA 状态灯显示信号";
CM_ SG_ 513 APAVcFbFrmADD "APA Voice Control Feedback
APA 语控开启反馈";
CM_ SG_ 513 APAVcQuitAvlFrmADD "APA Quit Availability
APA 退出可用信号";
CM_ SG_ 513 APAVcStsFrmADD "APA Voice Control Status for Voice Contrl
APA 功能状态to 语控";
CM_ SG_ 513 AReCamStsFrmADD "AVM Rear camera Status";
CM_ SG_ 513 ARiCamStsFrmADD "AVM Right camera Status";
CM_ SG_ 513 AVMOpnReqFrmADD "AVM Open Request
AVM 开启请求";
CM_ SG_ 513 AVPIcnDispStsFrmADD "AVP Icon Display Status
AVP状态灯显示信号";
CM_ SG_ 513 CameraStsforADBFrmADD "Camera Status for ADB";
CM_ SG_ 513 CameraStsFrmADD "camera Status
摄像头状态";
CM_ SG_ 513 F120CamStsFrmADD "F120 camera Status";
CM_ SG_ 513 F120DVRStsFrmADD "DVR F120 camera channel status";
CM_ SG_ 513 F30CamStsFrmADD "F30 camera Status";
CM_ SG_ 513 F30DVRStsFrmADD "DVR F30 camera channel status";
CM_ SG_ 513 FLidarStsFrmADD "front lidar working status";
CM_ SG_ 513 FUSSStsFrmADD "front USS working status";
CM_ SG_ 513 HPPActiveSubStsFrmADD "HPP Active Sub-State Machine Status
HPP 激活子状态机信号";
CM_ SG_ 513 HPPAlrtWarnFrmADD "HPP接管提醒";
CM_ SG_ 513 HPPAVPModSts "代客泊车模式";
CM_ SG_ 513 HPPBakMapDfltParkSlotDispFrmADD "后台静默图回放 使用默认车位确认";
CM_ SG_ 513 HPPDriverOperateDialogFrmADD "HPPDriverOperateDialog
HPP驾驶员操作提醒询问类";
CM_ SG_ 513 HPPDriverOperateInd2FrmADD "HPP Driver Operation Indicator2
HPP 驾驶员操作提示 动态文字类";
CM_ SG_ 513 HPPDriverOperateIndFrmADD "HPP Driver Operation Indicator
HPP 驾驶员操作提示";
CM_ SG_ 513 HPPIcnDispStsFrmADD "HPP Icon Display Status
HPP状态灯显示信号";
CM_ SG_ 513 HPPInfotipFrmADD "HPP过程中信息提示";
CM_ SG_ 513 HPPLearnSubStsFrmADD "HPP Learning Sub-State Machine Status
HPP 学习子状态机信号";
CM_ SG_ 513 HPPLrnVcFbFrmADD "HPP Learning Voice Control Feedback
HPP 学习语控反馈";
CM_ SG_ 513 HPPPlayBackPushFrmADD "HPP路线回放推荐";
CM_ SG_ 513 HPPQuitIndFrmADD "HPP Quit Indicator
HPP 功能退出提示";
CM_ SG_ 513 HPPRecoverButtonStsFrmADD "继续寻位泊车可用性";
CM_ SG_ 513 HPPRecoverIndFrmADD "HPP Recover Indicator
HPP 回放中断提示";
CM_ SG_ 513 HPPRouteInd2FrmADD "HPP Route Management Succeed Indicator
HPP 路线管理成功类信息提示";
CM_ SG_ 513 HPPRouteIndFrmADD "HPP Route Management Indicator
HPP 路线管理提示";
CM_ SG_ 513 HPPRouteManageStsFrmADD "HPP 路线管理状态";
CM_ SG_ 513 HPPUnableToActiveIndFrmADD "HPP Unable to Active Indicator
HPP功能开启失败提示";
CM_ SG_ 513 HPPVehInParkSlotFrmADD "车辆是否处于车位内";
CM_ SG_ 513 IMUStsFrmADD "IMU working status";
CM_ SG_ 513 ISPLigtSnsrVFrmADD "ISP Light sensor value";
CM_ SG_ 513 LidarStsFrmADD "Lidar Status";
CM_ SG_ 513 ParkVicShdFrmADD "泊车语音屏蔽请求";
CM_ SG_ 513 PrkSteerWhlBtnLi "一键智驾泊车背光灯";
CM_ SG_ 513 ReCamStsFrmADD "Rear camera Status";
CM_ SG_ 513 ReDVRStsFrmADD "DVR Rear Camera channel status";
CM_ SG_ 513 RUSSStsFrmADD "rear USS working status";
CM_ SG_ 513 SLFCamStsFrmADD "Side Left Front camera Status";
CM_ SG_ 513 SLFDVRStsFrmADD "DVR Side Left Front camera channel status";
CM_ SG_ 513 SLLidarStsFrmADD "side left working status";
CM_ SG_ 513 SLRCamStsFrmADD "Side Left Rear camera Status";
CM_ SG_ 513 SLRDVRStsFrmADD "DVR Side Left Rear camera channel status";
CM_ SG_ 513 SnmDetInfoFrmADD "Sentry Detection Information";
CM_ SG_ 513 SnmDetResFrmADD "Sentry Mode Detection result";
CM_ SG_ 513 SnmF120CamDetResFrmADD "Sentry Mode F120 camera detection result";
CM_ SG_ 513 SnmReCamDetResFrmADD "Sentry Mode Rear camera detection result";
CM_ SG_ 513 SnmSLFCamDetResFrmADD "Sentry Mode Side Left Front camera detection result";
CM_ SG_ 513 SnmSLRCamDetResFrmADD "Sentry Mode Side Left Rear camera detection result";
CM_ SG_ 513 SnmSRFCamDetResFrmADD "Sentry Mode Side Right Front detection result";
CM_ SG_ 513 SnmSRRCamDetResFrmADD "Sentry Mode Side Right Rear camera detection result";
CM_ SG_ 513 SRFCamStsFrmADD "Side Right Front camera Status";
CM_ SG_ 513 SRFDVRStsFrmADD "DVR Side Right Front camera channel status";
CM_ SG_ 513 SRLidarStsFrmADD "side right working status";
CM_ SG_ 513 SRRCamStsFrmADD "Side Right Rear camera Status";
CM_ SG_ 513 SRRDVRStsFrmADD "DVR Side Rear Rear camera channel status";
CM_ SG_ 516 APAAlrtWarnFrmADD "APAAlrtWarnFrmADD
APA Alert紧急接管提示";
CM_ SG_ 516 APAButtonReqFrmADD "APA ParkIn or Parkout Button Display Request
开始泊入或开始泊出按钮显示请求";
CM_ SG_ 516 APARPAActiveSubFunFrmADD "APA RPA Activated function
APA RPA 被激活的功能";
CM_ SG_ 516 APARPADriverOperateInd2FrmADD "APA RPA Driver operating indication
APA RPA 驾驶员操作提示2";
CM_ SG_ 516 APARPADriverOperateIndFrmADD "APA RPA Driver operating indication
APA RPA 驾驶员操作提示";
CM_ SG_ 516 APARPAQuitReasonIndFrmADD "APA RPA quit reason indication
APA RPA完全退出原因提示";
CM_ SG_ 516 APARPARecoverIndFrmADD "APA RPA recovery interrupt indication
可恢复中断提示";
CM_ SG_ 516 APARPAstatusFrmADD "APA RPA status";
CM_ SG_ 516 APARPAUnableToActiveIndFrmADD "APA RPA Unable To Active indication
APA RPA无法激活原因提示";
CM_ SG_ 516 AVPCharLidCtrlFrmADD "AVP Charging Lid Control Request
AVP 充电盖控制请求";
CM_ SG_ 516 DriverlessStsFrmADD "无人功能使用状态";
CM_ SG_ 516 OutdoorPrkDrvrOperIndFrmADD "离车泊车操作提示";
CM_ SG_ 516 OutdoorPrkQuitIndFrmADD "离车泊车退出提示";
CM_ SG_ 516 OutdoorPrkRecoverIndFrmADD "离车泊车可恢复中断提示";
CM_ SG_ 516 OutdoorPrkUnableToActvIndFrmADD "离车泊车无法激活提示";
CM_ SG_ 516 ParkActiveRearSpoilerReqFrmADD "Parking Active Rear Spoiler Request
泊车电动尾翼请求";
CM_ SG_ 516 ParkAtmLiReqFrmADD "Parking system Atmosphere light Request";
CM_ SG_ 516 ParkBackMirrorUnfoldReqFrmADD "Parking system Back Mirroe Fold or Unfold Request";
CM_ SG_ 516 ParkCornrLiReqFrmADD "泊车对角灯的控制请求";
CM_ SG_ 516 ParkDoorLockReqFrmADD "Parking system Door Lock or unlock Request";
CM_ SG_ 516 ParkingPushFrmADD "泊车手机端push提示信号";
CM_ SG_ 516 ParkLoBeamReqFrmADD "Parking Low Beam Request
泊车近光灯请求";
CM_ SG_ 516 ParkMdlStsFrmADD "Parking Driver Model Status";
CM_ SG_ 516 ParkProgressSigReDistFrmADD "Parking progress single remain distance indication
泊车单步剩余距离";
CM_ SG_ 516 ParkTurnLiReqFrmADD "Parking system turn light request";
CM_ SG_ 516 ParkWindowReqFrmADD "Parking system Window Closed Request";
CM_ SG_ 516 PASBuzzerWarnMuteIndFrmADD "PAS静音提示";
CM_ SG_ 516 PRAMoveSigReDistFrmADD "RPA Move single remain distance indication遥控移车单步剩余距离";
CM_ SG_ 516 PrkgHornReqFrmADD "parking horn request";
CM_ SG_ 516 RPAAvailableFrmADD "RPA Available Signal
RPA 可用信号";
CM_ SG_ 516 RPADriverOperateIndFrmADD "RPA操作提示1";
CM_ SG_ 516 RPAOperateToastFrmADD "RPA操作提示2";
CM_ SG_ 516 RPAQuitReasonIndFrmADD "RPA退出提示";
CM_ SG_ 516 RPARecoverIndFrmADD "RPA可恢复中断提示";
CM_ SG_ 516 RPAUnableToActiveIndFrmADD "RPA无法激活提示";
CM_ SG_ 516 WeatherStsFrmADD "Weather Status";
CM_ SG_ 518 BndryLeftAng1FrmADD "Boundary1 Left Angle";
CM_ SG_ 518 BndryLeftAng2FrmADD "Boundary2 Left Angle";
CM_ SG_ 518 BndryLeftAng3FrmADD "Boundary3 Left Angle";
CM_ SG_ 518 BndryLeftAng4FrmADD "Boundary4 Left Angle";
CM_ SG_ 518 BndryLeftAng5FrmADD "Boundary5 Left Angle";
CM_ SG_ 518 BndryLeftDist1FrmADD "Boundary1 Left Distance";
CM_ SG_ 518 BndryLeftDist2FrmADD "Boundary2 Left Distance";
CM_ SG_ 518 BndryLeftDist3FrmADD "Boundary3 Left Distance";
CM_ SG_ 518 BndryLeftDist4FrmADD "Boundary4 Left Distance";
CM_ SG_ 518 BndryLeftDist5FrmADD "Boundary5 Left Distance";
CM_ SG_ 518 BndryLowerAng1FrmADD "Boundary1 Lower Angle";
CM_ SG_ 518 BndryLowerAng2FrmADD "Boundary2 Lower Angle";
CM_ SG_ 518 BndryLowerAng3FrmADD "Boundary3 Lower Angle";
CM_ SG_ 518 BndryLowerAng4FrmADD "Boundary3 Lower Angle";
CM_ SG_ 518 BndryLowerAng5FrmADD "Boundary5 Lower Angle";
CM_ SG_ 518 BndryLowerDist1FrmADD "Boundary1 Lower Distance";
CM_ SG_ 518 BndryLowerDist2FrmADD "Boundary2 Lower Distance";
CM_ SG_ 518 BndryLowerDist3FrmADD "Boundary3 Lower Distance";
CM_ SG_ 518 BndryLowerDist4FrmADD "Boundary3 Lower Distance";
CM_ SG_ 518 BndryLowerDist5FrmADD "Boundary5 Lower Distance";
CM_ SG_ 518 VehObjDist1FrmADD "Vehicle1 Object Distance";
CM_ SG_ 518 VehObjDist2FrmADD "Vehicle2 Object Distance";
CM_ SG_ 518 VehObjDist3FrmADD "Vehicle3 Object Distance";
CM_ SG_ 518 VehObjDist4FrmADD "Vehicle4 Object Distance";
CM_ SG_ 518 VehObjDist5FrmADD "Vehicle5 Object Distance";
CM_ SG_ 518 VehObjDist6FrmADD "Vehicle6 Object Distance";
CM_ SG_ 518 VehObjDist7FrmADD "Vehicle7 Object Distance";
CM_ SG_ 518 VehObjDist8FrmADD "Vehicle8 Object Distance";
CM_ SG_ 518 VehObjHorzCtrAng1FrmADD "Vehicle1 Object horizontal center angle";
CM_ SG_ 518 VehObjHorzCtrAng2FrmADD "Vehicle2 Object horizontal center angle";
CM_ SG_ 518 VehObjHorzCtrAng3FrmADD "Vehicle3 Object horizontal center angle";
CM_ SG_ 518 VehObjHorzCtrAng4FrmADD "Vehicle4 Object horizontal center angle";
CM_ SG_ 518 VehObjHorzCtrAng5FrmADD "Vehicle5 Object horizontal center angle";
CM_ SG_ 518 VehObjHorzCtrAng6FrmADD "Vehicle6 Object horizontal center angle";
CM_ SG_ 518 VehObjHorzCtrAng7FrmADD "Vehicle7 Object horizontal center angle";
CM_ SG_ 518 VehObjHorzCtrAng8FrmADD "Vehicle8 Object horizontal center angle";
CM_ SG_ 518 VehObjHorzWidthAng1FrmADD "Vehicle1 Object horizontal width angle";
CM_ SG_ 518 VehObjHorzWidthAng2FrmADD "Vehicle2 Object horizontal width angle";
CM_ SG_ 518 VehObjHorzWidthAng3FrmADD "Vehicle3 Object horizontal width angle";
CM_ SG_ 518 VehObjHorzWidthAng4FrmADD "Vehicle4 Object horizontal width angle";
CM_ SG_ 518 VehObjHorzWidthAng5FrmADD "Vehicle5 Object horizontal width angle";
CM_ SG_ 518 VehObjHorzWidthAng6FrmADD "Vehicle6 Object horizontal width angle";
CM_ SG_ 518 VehObjHorzWidthAng7FrmADD "Vehicle7 Object horizontal width angle";
CM_ SG_ 518 VehObjHorzWidthAng8FrmADD "Vehicle8 Object horizontal width angle";
CM_ SG_ 519 BndryRightAng1FrmADD "Boundary1 Right Angle";
CM_ SG_ 519 BndryRightAng2FrmADD "Boundary2 Right Angle";
CM_ SG_ 519 BndryRightAng3FrmADD "Boundary3 Right Angle";
CM_ SG_ 519 BndryRightAng4FrmADD "Boundary4 Right Angle";
CM_ SG_ 519 BndryRightAng5FrmADD "Boundary5 Right Angle";
CM_ SG_ 519 BndryRightDist1FrmADD "Boundary1 Right Distance";
CM_ SG_ 519 BndryRightDist2FrmADD "Boundary2 Right Distance";
CM_ SG_ 519 BndryRightDist3FrmADD "Boundary3 Right Distance";
CM_ SG_ 519 BndryRightDist4FrmADD "Boundary3 Right Distance";
CM_ SG_ 519 BndryRightDist5FrmADD "Boundary5 Right Distance";
CM_ SG_ 519 BndryValidity1FrmADD "Boundary1 Validity";
CM_ SG_ 519 BndryValidity2FrmADD "Boundary2 Validity";
CM_ SG_ 519 BndryValidity3FrmADD "Boundary3 Validity";
CM_ SG_ 519 BndryValidity4FrmADD "Boundary4 Validity";
CM_ SG_ 519 BndryValidity5FrmADD "Boundary5 Validity";
CM_ SG_ 519 EnvIllumFrmADD "Environment Illumination From ADD
智驾感知识别环境亮度";
CM_ SG_ 519 RoadCondDistFrmADD "Road Condition Distance From ADD
距离下一个特征工况的距离";
CM_ SG_ 519 RoadConditionFrmADD "Road Condition From ADD
图层道路颠簸工况";
CM_ SG_ 519 RoadCondLenthFrmADD "Road Condition Length From ADD
连续特征工况的长度";
CM_ SG_ 519 TooManyBndryFlagFrmADD "Too Many Boundary Flag";
CM_ SG_ 519 TooManyVehFlagFrmADD "Too Many vehice Flag";
CM_ SG_ 519 TrafSignDist1FrmADD "Traffic sign1 Object Distance";
CM_ SG_ 519 TrafSignDist2FrmADD "Traffic sign2 Object Distance";
CM_ SG_ 519 TrafSignHorzCtrAng1FrmADD "Traffic sign1 Object horizontal center angle";
CM_ SG_ 519 TrafSignHorzCtrAng2FrmADD "Traffic sign2 Object horizontal center angle";
CM_ SG_ 519 TrafSignHorzWidthAng1FrmADD "Traffic sign1 Object horizontal width angle";
CM_ SG_ 519 TrafSignHorzWidthAng2FrmADD "Traffic sign2 Object horizontal width angle";
CM_ SG_ 519 TrafSignID1FrmADD "Traffic sign1 Object ID";
CM_ SG_ 519 TrafSignID2FrmADD "Traffic sign2 Object ID";
CM_ SG_ 519 TrafSignValidity1FrmADD "Traffic sign1 Object validity";
CM_ SG_ 519 TrafSignValidity2FrmADD "Traffic sign2 Object validity";
CM_ SG_ 519 VehObjDir1FrmADD "Vehicle1 Object Direciton";
CM_ SG_ 519 VehObjDir2FrmADD "Vehicle2 Object Direciton";
CM_ SG_ 519 VehObjDir3FrmADD "Vehicle3 Object Direciton";
CM_ SG_ 519 VehObjDir4FrmADD "Vehicle4 Object Direciton";
CM_ SG_ 519 VehObjDir5FrmADD "Vehicle5 ObjectDireciton";
CM_ SG_ 519 VehObjDir6FrmADD "Vehicle6 Object Direciton";
CM_ SG_ 519 VehObjDir7FrmADD "Vehicle7 Object Direciton";
CM_ SG_ 519 VehObjDir8FrmADD "Vehicle8 Object Direciton";
CM_ SG_ 519 VehObjID1FrmADD "Vehicle1 Object ID";
CM_ SG_ 519 VehObjID2FrmADD "Vehicle2 Object ID";
CM_ SG_ 519 VehObjID3FrmADD "Vehicle3 Object ID";
CM_ SG_ 519 VehObjID4FrmADD "Vehicle4 Object ID";
CM_ SG_ 519 VehObjID5FrmADD "Vehicle5 Object ID";
CM_ SG_ 519 VehObjID6FrmADD "Vehicle6 Object ID";
CM_ SG_ 519 VehObjID7FrmADD "Vehicle7 Object ID";
CM_ SG_ 519 VehObjID8FrmADD "Vehicle8 Object ID";
CM_ SG_ 519 VehObjType1FrmADD "Vehicle1 Object type";
CM_ SG_ 519 VehObjType2FrmADD "Vehicle2 Object type";
CM_ SG_ 519 VehObjType3FrmADD "Vehicle3 Object type";
CM_ SG_ 519 VehObjType4FrmADD "Vehicle4 Object type";
CM_ SG_ 519 VehObjType5FrmADD "Vehicle5 Object type";
CM_ SG_ 519 VehObjType6FrmADD "Vehicle6 Object type";
CM_ SG_ 519 VehObjType7FrmADD "Vehicle7 Object type";
CM_ SG_ 519 VehObjType8FrmADD "Vehicle8 Object type";
CM_ SG_ 519 VehObjValidity1FrmADD "Vehicle1 Object validity";
CM_ SG_ 519 VehObjValidity2FrmADD "Vehicle2 Object validity";
CM_ SG_ 519 VehObjValidity3FrmADD "Vehicle3 Object validity";
CM_ SG_ 519 VehObjValidity4FrmADD "Vehicle4 Object validity";
CM_ SG_ 519 VehObjValidity5FrmADD "Vehicle5 Object validity";
CM_ SG_ 519 VehObjValidity6FrmADD "Vehicle6 Object validity";
CM_ SG_ 519 VehObjValidity7FrmADD "Vehicle7 Object validity";
CM_ SG_ 519 VehObjValidity8FrmADD "Vehicle8 Object validity";
CM_ SG_ 528 ADDSyncFVReq "ADD同步请求";
CM_ SG_ 661 ADSRCTBBrkReqFrmADD "ADD发出的RCTB制动请求状态";
CM_ SG_ 661 ADSRCTBTarDecelFrmADD "ADD发出的RCTB减速度请求";
CM_ SG_ 661 BmpTrk1ConfFrmADD "Bumpy Track Type conf";
CM_ SG_ 661 BmpTrk1HeiFrmADD "Bumpy Track Height";
CM_ SG_ 661 BmpTrk1TypFrmADD "Bumpy Track Type";
CM_ SG_ 661 BmpTrk2ConfFrmADD "减速带2置信度
Bumpy Track Confidence level";
CM_ SG_ 661 BmpTrk2HeiFrmADD "减速带2高度
Bumpy Track Height";
CM_ SG_ 661 BmpTrk2TypFrmADD "Bumpy Track Type
减速带类型";
CM_ SG_ 661 Road1EndPotXRiFrmADD "减速带1右侧终止点 X坐标
Road1 End PointX Right";
CM_ SG_ 661 Road1EndPotYRiFrmADD "Road1 End PointY right";
CM_ SG_ 661 Road1StrtPotXLeFrmADD "减速带1 左侧起始点 X坐标
Road1 Start PointX left";
CM_ SG_ 661 Road1StrtPotYLeFrmADD "Road1 Start PointY left";
CM_ SG_ 661 Road2EndPotXRiFrmADD "减速带2右侧终止点 X坐标
Road1 End PointX Right";
CM_ SG_ 661 Road2EndPotYRiFrmADD "Road2 End PointY right";
CM_ SG_ 661 Road2StrtPotXLeFrmADD "减速带2 左侧起始点 X坐标
Road1 Start PointX left";
CM_ SG_ 661 Road2StrtPotYLeFrmADD "Road2 Start PointY left";
BA_DEF_  "BaudRateCANFD" FLOAT 1000 10000000;
BA_DEF_  "Baudrate" INT 1000 1000000;
BA_DEF_  "BusType" STRING ;
BA_DEF_  "DBName" STRING ;
BA_DEF_  "ProtocolType" STRING ;
BA_DEF_ BU_  "NmAsrNode" ENUM  "No","Yes";
BA_DEF_ BO_  "CANFD_BRS" ENUM  "0","1";
BA_DEF_ BO_  "GenMsgCycleTime" INT 0 30000;
BA_DEF_ BO_  "GenMsgCycleTimeFast" INT 0 30000;
BA_DEF_ BO_  "GenMsgDelayTime" INT 0 100000;
BA_DEF_ BO_  "GenMsgNrOfRepetition" INT 0 100000;
BA_DEF_ BO_  "GenMsgSendType" ENUM  "cyclic","spontaneous","cyclicIfActive","spontaneousWithDelay","cyclicAndSpontaneous","cyclicAndSpontaneousWithDelay","IfActive","NoMsgSendType";
BA_DEF_ BO_  "GenMsgStartDelayTime" INT 0 100000;
BA_DEF_ BO_  "NmAsrBaseAddress" HEX 0 536870911;
BA_DEF_ BO_  "NmAsrMessage" ENUM  "No","Yes";
BA_DEF_ BO_  "VFrameFormat" ENUM  "StandardCAN","ExtendedCAN","reserved","J1939PG","reserved","reserved","reserved","reserved","reserved","reserved","reserved","reserved","reserved","reserved","StandardCAN_FD","ExtendedCAN_FD";
BA_DEF_ SG_  "GenSigSendType" ENUM  "Cyclic","OnWrite","OnWriteWithRepetition","OnChange","OnChangeWithRepetition","IfActive","IfActiveWithRepetition","NoSigSendType";
BA_DEF_ SG_  "GenSigStartValue" FLOAT -1.79769313486232E+308 1.84467440737096E+019;
BA_DEF_DEF_  "BaudRateCANFD" 1000;
BA_DEF_DEF_  "Baudrate" 1000;
BA_DEF_DEF_  "BusType" "CANFD";
BA_DEF_DEF_  "DBName" "";
BA_DEF_DEF_  "ProtocolType" "";
BA_DEF_DEF_  "NmAsrNode" "Yes";
BA_DEF_DEF_  "CANFD_BRS" "1";
BA_DEF_DEF_  "GenMsgCycleTime" 0;
BA_DEF_DEF_  "GenMsgCycleTimeFast" 0;
BA_DEF_DEF_  "GenMsgDelayTime" 0;
BA_DEF_DEF_  "GenMsgNrOfRepetition" 0;
BA_DEF_DEF_  "GenMsgSendType" "";
BA_DEF_DEF_  "GenMsgStartDelayTime" 0;
BA_DEF_DEF_  "NmAsrBaseAddress" 1280;
BA_DEF_DEF_  "NmAsrMessage" "No";
BA_DEF_DEF_  "VFrameFormat" "J1939PG";
BA_DEF_DEF_  "GenSigSendType" "Cyclic";
BA_DEF_DEF_  "GenSigStartValue" 0;
BA_ "ProtocolType" "CAN";
BA_ "BusType" "CAN FD";
BA_ "Baudrate" 500000;
BA_ "BaudRateCANFD" 2000000;
BA_ "DBName" "ADD_ChassisFusionCANFD";
BA_ "GenMsgSendType" BO_ 379 0;
BA_ "GenMsgCycleTime" BO_ 379 20;
BA_ "VFrameFormat" BO_ 379 14;
BA_ "GenMsgSendType" BO_ 399 0;
BA_ "GenMsgCycleTime" BO_ 399 20;
BA_ "VFrameFormat" BO_ 399 14;
BA_ "GenMsgSendType" BO_ 493 0;
BA_ "GenMsgCycleTime" BO_ 493 50;
BA_ "VFrameFormat" BO_ 493 14;
BA_ "GenMsgSendType" BO_ 512 0;
BA_ "GenMsgCycleTime" BO_ 512 50;
BA_ "VFrameFormat" BO_ 512 14;
BA_ "GenMsgSendType" BO_ 513 0;
BA_ "GenMsgCycleTime" BO_ 513 50;
BA_ "VFrameFormat" BO_ 513 14;
BA_ "GenMsgSendType" BO_ 516 0;
BA_ "GenMsgCycleTime" BO_ 516 50;
BA_ "VFrameFormat" BO_ 516 14;
BA_ "GenMsgSendType" BO_ 518 0;
BA_ "GenMsgCycleTime" BO_ 518 50;
BA_ "VFrameFormat" BO_ 518 14;
BA_ "GenMsgSendType" BO_ 519 0;
BA_ "GenMsgCycleTime" BO_ 519 50;
BA_ "VFrameFormat" BO_ 519 14;
BA_ "GenMsgSendType" BO_ 528 1;
BA_ "GenMsgDelayTime" BO_ 528 10;
BA_ "VFrameFormat" BO_ 528 14;
BA_ "GenMsgSendType" BO_ 661 0;
BA_ "GenMsgCycleTime" BO_ 661 20;
BA_ "VFrameFormat" BO_ 661 14;
BA_ "GenSigStartValue" SG_ 512 DrvMdlStsFrmADD 1;
BA_ "GenSigStartValue" SG_ 516 ParkProgressSigReDistFrmADD 511;
BA_ "GenSigStartValue" SG_ 516 PRAMoveSigReDistFrmADD 255;
BA_ "GenSigSendType" SG_ 528 ADDSyncFVReq 1;
BA_ "GenSigStartValue" SG_ 661 ADSRCTBTarDecelFrmADD 200;
VAL_ 379 ADDKeepAwakeReq 0 "No_request" 1 "Request" ;
VAL_ 379 ParkGearReqEnaFrmADD 0 "No_Request" 1 "Request" 2 "Failure" ;
VAL_ 379 ParkGearReqFrmADD 0 "Norequest" 1 "P" 2 "R" 3 "N" 4 "D" ;
VAL_ 379 RPAHVOnReqFrmADD 0 "No_request" 1 "Request" ;
VAL_ 379 RPAPrkinRecdFrmADD 0 "Default" 1 "RPA_In" 2 "Manual_In" 3 "Reserved" ;
VAL_ 399 HPPAVPRecoverIndCtrlBkp 0 "No_Request" 1 "Request" ;
VAL_ 399 HPPAVPSteerWhlCtrlReqStsBkp 0 "NoRequest" 1 "Ready" 2 "active" 3 "Failure" ;
VAL_ 493 DrvAirSuspReqFrmADD 0 "no_request" 1 "request" ;
VAL_ 493 ParkAirSuspReqFrmADD 0 "No_Request" 1 "Request_Forbid" 2 "Request_LiftToNL" 3 "Request_LiftToHL" ;
VAL_ 512 ADDBSDLCAStsFrmADD 0 "Off" 1 "Standby" 2 "Active" 3 "Failure" ;
VAL_ 512 ADSAEBStsFrmADD 0 "Off" 1 "Standby" 2 "Active" 3 "Failure" 4 "Reserved" 5 "Reserved" 6 "Reserved" 7 "Reserved" ;
VAL_ 512 ADSAEBTarDirFrmADD 0 "default" 1 "Left" 2 "Middle" 3 "Right" 4 "unavailable" ;
VAL_ 512 ADSAEBWarnReqFrmADD 0 "no_warning" 1 "warning_level_1" 2 "reserved" 3 "reserved" ;
VAL_ 512 AdsAutoTurnLiCnclReqFrmADD 0 "No_request" 1 "Cancel_left_request" 2 "Cancel_right_request" ;
VAL_ 512 AdsAutoTurnLiSwtStsFrmADD 0 "Default" 1 "Off" 2 "On" 3 "Off_not_support_click" 4 "On_not_support_click" 5 "Unavailable" ;
VAL_ 512 AdsAutoTurnLiUnavlRsnFrmADD 0 "default" 1 "No_reason_req" 2 "not_P_gear" 3 "account_not_log_in" 4 "not_authorized" 5 "Pilot_active" 6 "privacy_mode" 7 "extreme_eco_mode" 8 "lowpower_mode" 9 "parking_function_active" 10 "adas_not_purchased" 11 "Error_detected" 12 "NOA_active" 13 "Reserved_1" 14 "Reserved_2" ;
VAL_ 512 ADSBSDLCAAudioWarnReqFrmADD 0 "default" 1 "no_request" 2 "audio_request" ;
VAL_ 512 ADSBSDLCAWarnReqLeFrmADD 0 "no_warning" 1 "warning_level_1" 2 "warning_level_2" ;
VAL_ 512 ADSBSDLCAWarnReqRiFrmADD 0 "no_warning" 1 "warning_level_1" 2 "warning_level_2" ;
VAL_ 512 ADSBSDLightWarningLeReqFrmADD 0 "no_request" 1 "warning_level1" 2 "warning_level2" ;
VAL_ 512 ADSBSDLightWarningRiReqFrmADD 0 "no_request" 1 "warning_level1" 2 "warning_level2" ;
VAL_ 512 ADSDOWStsFrmADD 0 "Off" 1 "Standby" 2 "Active" 3 "Failure" ;
VAL_ 512 ADSDOWWarnReqFrLeFrmADD 0 "no_warning" 1 "warning_level_1" 2 "warning_level_2" 3 "reserved" ;
VAL_ 512 ADSDOWWarnReqFrRiFrmADD 0 "no_warning" 1 "warning_level_1" 2 "warning_level_2" 3 "reserved" ;
VAL_ 512 ADSDOWWarnReqReLeFrmADD 0 "no_warning" 1 "warning_level_1" 2 "warning_level_2" 3 "reserved" ;
VAL_ 512 ADSDOWWarnReqReRiFrmADD 0 "no_warning" 1 "warning_level_1" 2 "warning_level_2" 3 "reserved" ;
VAL_ 512 ADSELKStsFrmADD 0 "Off" 1 "Standby" 2 "NoWarning" 3 "LeftOverride" 4 "LeftWarning" 5 "RightOverride" 6 "RightWarning" 7 "Fault" ;
VAL_ 512 ADSESSStsFrmADD 0 "Off" 1 "Standby" 2 "Active" 3 "Failure" 4 "Reserved" 5 "Reserved" 6 "Reserved" 7 "Reserved" ;
VAL_ 512 ADSESSWarnReqFrmADD 0 "NoRequest" 1 "Request" ;
VAL_ 512 ADSFCWReqFrmADD 0 "no_warning" 1 "warning_level_1" 2 "warning_level_2" ;
VAL_ 512 ADSFCWStsFrmADD 0 "Off" 1 "Standby" 2 "Active" 3 "Failure" 4 "Reserved" 5 "Reserved" 6 "Reserved" 7 "Reserved" ;
VAL_ 512 AdsIntelgntSpdSwtStsFrmADD 0 "Default" 1 "Off" 2 "On" 3 "Off_not_support_click" 4 "On_not_support_click" 5 "Unavailable" ;
VAL_ 512 AdsIntelgntSpdUnavlRsnFrmADD 0 "default" 1 "No_reason_req" 2 "Map_error" 3 "Error_detected" 4 "Reserved_1" 5 "Reserved_2" ;
VAL_ 512 ADSLDPHandOffExitFrmADD 0 "No_Request" 1 "Request" ;
VAL_ 512 ADSLDPHandOffWarningFrmADD 0 "No_request" 1 "WarningLevel1" 2 "WarningLevel2" 3 "WarningLevel3" ;
VAL_ 512 ADSLDPStsFrmADD 0 "Off" 1 "Standby" 2 "NoWarning" 3 "LeftOverride" 4 "LeftWarning" 5 "RightOverride" 6 "RightWarning" 7 "Fault" ;
VAL_ 512 ADSLDPWarnReqLeFrmADD 0 "NoRequest" 1 "Request" ;
VAL_ 512 ADSLDPWarnReqRiFrmADD 0 "NoRequest" 1 "Request" ;
VAL_ 512 ADSLDWStsFrmADD 0 "Off" 1 "Standby" 2 "NoWarning" 3 "LeftOverride" 4 "LeftWarning" 5 "RightOverride" 6 "RightWarning" 7 "Fault" ;
VAL_ 512 ADSLDWWarnLeReqFrmADD 0 "NoRequest" 1 "request" ;
VAL_ 512 ADSLDWWarnRiReqFrmADD 0 "NoRequest" 1 "request" ;
VAL_ 512 AdsLearnSwtStsFrmADD 0 "Default" 1 "No_Display" 2 "Display" 3 "Display_not_support_click" ;
VAL_ 512 AdsLearnSwtUnavlRsnFrmADD 0 "default" 1 "No_reason_req" 2 "not_P_gear" 3 "account_not_log_in" 4 "not_authorized" 5 "Reserved_1" 6 "privacy_mode" 7 "extreme_eco_mode" 8 "lowpower_mode" 9 "Reserved_2" 10 "adas_not_purchased" 11 "Error_detected" 12 "Reserved_3" ;
VAL_ 512 ADSLiReqFrmADD 0 "no_request" 1 "request" ;
VAL_ 512 ADSMAIInhibitReqFrmADD 0 "no_request" 1 "request" 2 "reseved1" 3 "reseved2" ;
VAL_ 512 ADSMAIStsFrmADD 0 "Off" 1 "Passive" 2 "Standby" 3 "ActiveInhibit" 4 "ActiveWarning" 5 "Fault" 6 "Reserved1" 7 "Reserved2" ;
VAL_ 512 ADSMAIWarnReqFrmADD 0 "no_request" 1 "request" 2 "reseved1" 3 "reseved2" ;
VAL_ 512 AdsModSwtStsFrmADD 0 "Default" 1 "ACC_On" 2 "LCC_On" 3 "NOA_On" 4 "ACC_On_NOA_Not_Support_Click" 5 "LCC_On_NOA_Not_Support_Click" 6 "ACC_On_LCC_Not_Support_Click" 7 "ACC_On_All_Not_Support_Click" 8 "LCC_On_All_Not_Support_Click" 9 "NOA_On_All_Not_Support_Click" 10 "Unavailable" ;
VAL_ 512 AdsNOAOddSwtStsFrmADD 0 "Default" 1 "Highway" 2 "Urban_road" 3 "Highway_and_Urban_road" 4 "HNOA_Active" 5 "CNOA_Active" 6 "CNOA_not_support_click" 7 "unavailable" ;
VAL_ 512 AdsNOAOddSwtUnavlRsnFrmADD 0 "default" 1 "No_reason_req" 2 "Hnoa_active" 3 "Cnoa_active" 4 "CNOA_not_learned" 5 "Error_detected" 6 "reserved_1" 7 "reserved_2" ;
VAL_ 512 ADSRCTAStsFrmADD 0 "Off" 1 "Standby" 2 "Active" 3 "Failure" ;
VAL_ 512 ADSRCTAWarnReqLeFrmADD 0 "no_warning" 1 "warning_level_1" 2 "warning_level_2" ;
VAL_ 512 ADSRCTAWarnReqRiFrmADD 0 "no_warning" 1 "warning_level_1" 2 "warning_level_2" ;
VAL_ 512 ADSRCTBStsFrmADD 0 "Off" 1 "Standby" 2 "Active" 3 "Failure" ;
VAL_ 512 ADSRCTBWarnReqLeFrmADD 0 "no_warning" 1 "warning_level_1" 2 "warning_level_2" ;
VAL_ 512 ADSRCTBWarnReqRiFrmADD 0 "no_warning" 1 "warning_level_1" 2 "warning_level_2" ;
VAL_ 512 ADSRCWStsFrmADD 0 "Off" 1 "Standby" 2 "Active" 3 "Failure" ;
VAL_ 512 ADSRCWWarnReqFrmADD 0 "no_warning" 1 "warning_level_1" 2 "warning_level_2" ;
VAL_ 512 ADSSysErrorRmdFrmADD 0 "default" 1 "fault" 2 "reserved_1" 3 "reserved_2" ;
VAL_ 512 ADSSysErrorStsFrmADD 0 "default" 1 "fault" 2 "reserved_1" 3 "reserved_2" ;
VAL_ 512 ADSTakeoverRmdFrmADD 0 "default" 1 "takeover_adc" 2 "takeover_adp" 3 "reserved_1" ;
VAL_ 512 ADSTLAStsFrmADD 0 "Off" 1 "Standby" 2 "Active1" 3 "Active2" 4 "Failure" ;
VAL_ 512 AdsTrfcLiCtrlSwtStsFrmADD 0 "Default" 1 "Off" 2 "On" 3 "Unavailable" ;
VAL_ 512 ADSVcCtrlArbFrmADD 0 "No_Conflict" 1 "Conflict" 2 "Reserved" 3 "Reserved" ;
VAL_ 512 AdsVehDetourSwtStsFrmADD 0 "Default" 1 "Off" 2 "On" 3 "Unavailable" ;
VAL_ 512 AEBTarObjClassFrmADD 0 "Unknown" 1 "4_wheeler" 2 "2_wheeler" 3 "Pedestrian" ;
VAL_ 512 AutoDrvLaneChgStsFrmADD 0 "unavailable" 1 "passive" 2 "standby" 3 "LaneChangeWaiting" 4 "LaneChangelateralmovement" 5 "LaneChangeChangeManoeuvre" 6 "LaneChangeChangeReturning" 7 "LaneChangeTakeover" 8 "LaneChangeFinish" ;
VAL_ 512 AVMCamVideoChainSts 0 "Normal" 1 "Error Level1" 2 "Error Level2" 3 "Reserved" ;
VAL_ 512 DrvAtmLiReqFrmADD 0 "NoRequest" 1 "Request" ;
VAL_ 512 DrvGearReqFrmADD 0 "Norequest" 1 "P" 2 "R" 3 "N" 4 "D" ;
VAL_ 512 DrvGearReqVldFrmADD 0 "Invalid" 1 "Valid" ;
VAL_ 512 DrvHUDDspFrmADD 0 "no_display" 1 "NOA_Active" 2 "NOA_Quit" 3 "Pilot_Active" 4 "Pilot_Quit" 5 "ACC_Active" 6 "ACC_Quit" 7 "ALC_active_left" 8 "ALC_active_right" 9 "ALC_warning_left" 10 "ALC_warning_right" ;
VAL_ 512 DrvLaneChgStsFrmADD 0 "unavailable" 1 "passive" 2 "standby" 3 "LaneChangeWaiting" 4 "LaneChangelateralmovement" 5 "LaneChangeChangeManoeuvre" 6 "LaneChangeChangeReturning" 7 "LaneChangeTakeover" 8 "LaneChangeFinish" ;
VAL_ 512 DrvMdlStsFrmADD 0 "NoRequest" 1 "DrivingModel_1" 2 "DrivingModel_2" 3 "DrivingMode_3" 4 "DrivingMode_4" ;
VAL_ 512 DrvNOARemdFrmADD 0 "no_display" 1 "NOA_active" 2 "NOA_quit" 3 "upgrade_to_NOA" 4 "degrade_to_LCC" 5 "degrade_to_ACC" 6 "rerouting_due_to_navigation_failed_" 7 "upgrade_to_NOA_due_to_Navigation_vaild" 8 "degrade_to_LCC_due_to_Navigation_failed" 9 "About_to_reroute" 10 "degrade_to_LCC_due_to_out_of_range" 11 "function_quit_due_to_arrive" 12 "NOA_vaild_reminder" 13 "entry_ramp_towards_left" 14 "entry_ramp_towards_right" 15 "entry_ramp_with_left_lever" 16 "entry_ramp_with_right_lever" 17 "inaccessible_ramp_and_left_lane_change" 18 "inaccessible_ramp_and_right_lane_change" 19 "enter_and_to_left" 20 "enter__and_to_right" 21 "enter_and_to_left_lever" 22 "enter__and_to_right_lever" 23 "not_enter_and_towards_left" 24 "not_enter_and_towards_right" 25 "lane_change_fail_and_towards_left" 26 "lane_change_fail_and_towards_Right" 27 "cannot_be_merged" 28 "faster_lane_and_lever" 29 "better_lane_and_lever" 30 "avoid_the_truck_and_lever" 31 "traffic_jam_and_lever_" 32 "lane_change_left_and_lever" 33 "lane_change_right_and_lever" 34 "lane_merging_and_lever" 35 "lane_changing_and_lever" 36 "navigation_lane_change_and_lever" 37 "avoid_risk_lane_and_lever" 38 "approaching_the_red_light" 39 "remind_to_traffic_light" 40 "waiting_area_confirm" 41 "NOA_quit_and_turn_around" 42 "Accelerator_pedal_confirm" 43 "take_over_remind" 44 "waiting_for_pedestrians" 45 "waiting_and_drive_away" 46 "faster_lane" 47 "reserve" 48 "better_lane" 49 "avoid_the_truck" 50 "traffic_jam" 51 "lane_change_left" 52 "lane_change_right" 53 "lane_merging_" 54 "lane_changing" 55 "navigation_lane_change" 56 "avoid_risk_lane" ;
VAL_ 512 DrvPltSysStsFrmADD 0 "Fault" 1 "Passive" 2 "PilotStandby" 3 "PilotNormalActive" 4 "PilotOverride_Long" 5 "PilotOverride_Lat" 6 "pilotActiveOnlylgt" 7 "Pilotoverlay" 8 "StandActive" 9 "StandWait" 10 "Takeover" 11 "MRM" ;
VAL_ 512 DrvPnt2PntSysStsFrmADD 0 "Default" 1 "Passive" 2 "APA_Standby" 3 "HPP_Standby" 4 "Driving_Standby" 5 "Parking_Active" 6 "Driving_Active" 7 "APA_Parking_In" 8 "APA_Parking_Out" 9 "HPP_Parking_In" 10 "HPP_Parking_Out" 11 "Driving_to_Parking" 12 "Parking_to_Driving" 13 "Fault" 14 "Reserved_0" 15 "Reserved_1" 16 "Reserved_2" 17 "Reserved_3" 18 "Reserved_4" 19 "Reserved_5" 20 "Reserved_6" 21 "Reserved_7" ;
VAL_ 512 DrvrSeldDstLvlFrmADD 0 "NoGapSet" 1 "DistanceLevel1" 2 "DistanceLevel2" 3 "DistanceLevel3" 4 "DistanceLevel4" 5 "DistanceLevel5" 6 "Reserved" 7 "Reserved" ;
VAL_ 512 DrvSysWarnFrmADD 0 "NoRequest" 1 "WarningLevel1" 2 "WarningLevel2" 3 "WarningLevel3" 4 "WarningLevel4" 5 "WarningLevel5" 6 "WarningLevel0" 7 "Reserved" ;
VAL_ 512 DrvTurnLiReqFrmADD 0 "no_request" 1 "Left_turn_request" 2 "Right_turn_request" 3 "hazard_light_request" ;
VAL_ 512 IndcrCancelReqFrmADD 0 "Norequest" 1 "Request" ;
VAL_ 512 LidarCleanReqFrmADD 0 "NoReq" 1 "Req" ;
VAL_ 512 NOASysStsFrmADD 0 "Fault" 1 "Passive" 2 "NOAstandby" 3 "NOANormalActive" 4 "NOAOverride_Long" 5 "StandActive" 6 "StandWait" 7 "Overlay" 8 "Takeover" 9 "MRM" ;
VAL_ 512 NOATypFrmADD 0 "Default" 1 "HNOA" 2 "CNOA" 3 "Reserved_1" ;
VAL_ 512 TSASignQlyFrmADD 127 "invalid" ;
VAL_ 512 TSASignTypeFrmADD 0 "NotDetected" 1 "SpeedLimits" 2 "OvertakingSigns" 3 "StopYieldSigns" 4 "CityLimits_EntryExit" 5 "MotorwayHighway" 6 "PreferenceRoad" 7 "ResidentialAreaSigns" 8 "NoEntry_NoAll" 9 "DangerSigns" 10 "WeatherCondition" 11 "VehicleCategory" 12 "Exit" 13 "Zone" 63 "Unknown" ;
VAL_ 512 TSASpdLimitFrmADD 0 "No_display" 1 "Cancelled" 2 "5" 3 "10" 4 "15" 5 "20" 6 "25" 7 "30" 8 "35" 9 "40" 10 "45" 11 "50" 12 "55" 13 "60" 14 "65" 15 "70" 16 "75" 17 "80" 18 "85" 19 "90" 20 "95" 21 "100" 22 "105" 23 "110" 24 "115" 25 "120" 26 "125" 27 "130" ;
VAL_ 512 TSASpdLimitUnitFrmADD 0 "Unknown" 1 "kmph" 2 "Miph" 3 "Not_used" ;
VAL_ 512 UserFbReqFrmADD 0 "NoRequest" 1 "Request" ;
VAL_ 513 ADSAPPUnableOpenRsnFrmADD 0 "default" 1 "lowpower_mode" 2 "extreme_eco_mode" 3 "Error_detected" 4 "SettingsItemNotOpen" 5 "Privacy_mode" 6 "Reserved_1" 7 "Req_TLC" ;
VAL_ 513 ADSAVPStsFrmADD 0 "OFF" 1 "Passive" 2 "Standby" 3 "Ready" 4 "Active" 5 "RecoverInterrupt" 6 "Completed" 7 "Terminated" 8 "Failure" 9 "Reserved" ;
VAL_ 513 ADSHPPStsFrmADD 0 "OFF" 1 "Passive" 2 "Standby" 3 "Ready" 4 "Active" 5 "RecoverInterrupt" 6 "Completed" 7 "Terminated" 8 "Failure" 9 "RecoverTakeover" 10 "PreStandby" 11 "RoamCalculate" 12 "Reserved_1" 13 "Reserved_2" 14 "Reserved_3" 15 "Reserved_4" ;
VAL_ 513 ADSLRRSnsrStsFrmADD 0 "Normal" 1 "Blocked" 2 "Not_calibrated" 3 "Error" 4 "Reserved" 5 "Reserved" 6 "Reserved" 7 "Reserved" 8 "Reserved" ;
VAL_ 513 ADSRLSRSnsrStsFrmADD 0 "Normal" 1 "Blocked" 2 "Not_calibrated" 3 "Error" 4 "Reserved" 5 "Reserved" 6 "Reserved" 7 "Reserved" 8 "Reserved" ;
VAL_ 513 ADSRRSRSnsrStsFrmADD 0 "Normal" 1 "Blocked" 2 "Not_calibrated" 3 "Error" 4 "Reserved" 5 "Reserved" 6 "Reserved" 7 "Reserved" 8 "Reserved" ;
VAL_ 513 AFrCamStsFrmADD 0 "off" 1 "Standby" 2 "Normal" 3 "Blocked" 4 "Error" 5 "Reserved" 6 "Reserved" 7 "Reserved" ;
VAL_ 513 ALeCamStsFrmADD 0 "off" 1 "Standby" 2 "Normal" 3 "Blocked" 4 "Error" 5 "Reserved" 6 "Reserved" 7 "Reserved" ;
VAL_ 513 APAIcnDispStsFrmADD 0 "no_display" 1 "grey" 2 "light" 3 "yellow_unable_active" 4 "yellow_system_failure" 5 "reserved" 6 "reserved" 7 "reserved" ;
VAL_ 513 APAVcFbFrmADD 0 "No_Command" 1 "Start_Searching" 2 "Speed_High" 3 "Slope_out_of_Limit" 4 "Charging" 5 "ADAS_Function_Active" 6 "Bad_weather" 7 "System_Fail" 8 "Req_Gear_D" 9 "Req_Close_Door_Driver" 10 "Req_Close_Door_Passenger" 11 "Req_Close_Door_LeftRear" 12 "Req_Close_Door_RightRear" 13 "Req_Close_Front_Lid" 14 "Req_Close_Trunk_Lid" 15 "Low_Power_Mode" 16 "Extreme_Economic_Driving_Mode" 17 "Set_button" 18 "One-click_Privacy_Enable" 19 "Trailer_Mode" 20 "Rescue_Mode" 21 "Car_Wash_Mode" 22 "Tire_Change_Mode" 23 "Ejection_Mode" 24 "Snow_Mode" 25 "One-click_Frenzy_Mode" 26 "Track_Mode" 27 "Drift_Mode" 28 "ESC_Off" 29 "ODD_Not_Available" 30 "Not_Press_SSB" 31 "Driver_Door_Open" 32 "Sensor_fail" 33 "Related_ECU_fail" 34 "Comm_fail" 35 "Lidar_Blocked" 36 "SVS_Blocked" 37 "Other_reason" 38 "SOC_LOW" 39 "Close_door" ;
VAL_ 513 APAVcQuitAvlFrmADD 0 "Unavailable" 1 "Available" ;
VAL_ 513 APAVcStsFrmADD 0 "NotDuringAPA" 1 "DuringAPA" ;
VAL_ 513 AReCamStsFrmADD 0 "off" 1 "Standby" 2 "Normal" 3 "Blocked" 4 "Error" 5 "Reserved" 6 "Reserved" 7 "Reserved" ;
VAL_ 513 ARiCamStsFrmADD 0 "off" 1 "Standby" 2 "Normal" 3 "Blocked" 4 "Error" 5 "Reserved" 6 "Reserved" 7 "Reserved" ;
VAL_ 513 AVMOpnReqFrmADD 0 "NoCommand" 1 "2DAVM&Camera" 2 "2DAVM" 3 "Pending" ;
VAL_ 513 AVPIcnDispStsFrmADD 0 "no_display" 1 "grey" 2 "light" 3 "yellow_unable_active" 4 "yellow_system_failure" 5 "reserved" 6 "reserved" 7 "reserved" ;
VAL_ 513 CameraStsforADBFrmADD 0 "Unknown" 1 "Normal" 2 "Blocking" 3 "Fault" ;
VAL_ 513 CameraStsFrmADD 0 "Not_Blocked" 1 "Blocked" ;
VAL_ 513 F120CamStsFrmADD 0 "off" 1 "Standby" 2 "Normal" 3 "Blocked" 4 "Error" 5 "Reserved" 6 "Reserved" 7 "Reserved" ;
VAL_ 513 F120DVRStsFrmADD 0 "Idle" 1 "DVR_service_is_available" 2 "camera_is_not_available" 3 "processing_resource_is_not_available" 4 "connection_is_not_available" 5 "reserved" 6 "reserved" 7 "reserved" ;
VAL_ 513 F30CamStsFrmADD 0 "off" 1 "Standby" 2 "Normal" 3 "Blocked" 4 "Error" 5 "Reserved" 6 "Reserved" 7 "Reserved" ;
VAL_ 513 F30DVRStsFrmADD 0 "Idle" 1 "DVR_service_is_available" 2 "camera_is_not_available" 3 "reserved" 4 "reserved" 5 "reserved" 6 "reserved" 7 "reserved" ;
VAL_ 513 FLidarStsFrmADD 0 "normal" 1 "PerformanceDegradation" 2 "blocked" 3 "Error" 4 "Reserved" ;
VAL_ 513 FUSSStsFrmADD 0 "normal" 1 "blocked" 2 "Error" 3 "Reserved" ;
VAL_ 513 HPPActiveSubStsFrmADD 0 "Default" 1 "Cruising" 2 "Parking" 3 "Failure" ;
VAL_ 513 HPPAlrtWarnFrmADD 0 "No_Request" 1 "Learn_TakeOverWarnRequest" 2 "PlyBak_TakeOverWarnRequest" ;
VAL_ 513 HPPAVPModSts 0 "None" 1 "AVP_Parkin" 2 "HPP_Parkin" 3 "AVP_Parkout" 4 "HPP_Parkout" 5 "Reserved_1" 6 "Reserved_2" 7 "Reserved_3" ;
VAL_ 513 HPPBakMapDfltParkSlotDispFrmADD 0 "No_Request" 1 "HPPBackMapDfltParkSlotDisplayReq" ;
VAL_ 513 HPPDriverOperateDialogFrmADD 0 "No_Request" 1 "LearnOpr_DistanceOutofLimit_Lev2" 2 "LearnOpr_StudyOvertime_Lev2" 3 "LearnOpr_RDistanceOutofLimit_Lev2" 4 "LearnOpr_APATerminated" 5 "LearnOpr_ChooseFinishVehInSlot" 6 "LearnOpr_ChooseFinishVehNotInSlot" 7 "LearnOpr_ManualPVehInSlot" 8 "LearnOpr_ManualPVehNotInSlot" 9 "LearnOpr_OtherReason" 10 "Reserved_1" 11 "Reserved_2" 12 "Reserved_3" 13 "Reserved_4" 14 "Reserved_5" 15 "Req_TLC" ;
VAL_ 513 HPPDriverOperateInd2FrmADD 0 "No_Request" 1 "LearnOpr_ChooseParkSlot" 2 "LearnOpr_ReqClickStartAPAparkButton" 3 "LearnOpr_APATerminatedDriveToDestination" 4 "LearnOpr_HPPlearnCompleted" 5 "PlyBakOpr_StartPlyBak_Recommend(Releasesteerwheel&Brake)" 6 "PlyBakOpr_Recover_ClickStartAPAparkbutton" 7 "PlyBakOpr_Recover_ParkSlotOccpt_choseOth" 8 "PlyBakOpr_Recover_ZoneParkSlotOccpt_choseOth" 9 "PlyBakOpr_Recover_ParkSlotOccpt_choseOth_BckGrLine" 10 "PlyBakOpr_Recover_ClickRecoverHPPbutton" 11 "PlyBakOpr_Recover_DoorOpen" 12 "PlyBakOpr_Recover_EngineFrontDoorOpen" 13 "PlyBakOpr_Recover_TrunkOpen" 14 "PlyBakOpr_Recover_DriverSeatBeltNotTied" 15 "PlyBakOpr_Arriathend_choseOth" 16 "Pause_To_Active" 17 "Reserved_3" 18 "Reserved_4" 19 "Reserved_5" 20 "Reserved_6" 21 "Reserved_7" 22 "Reserved_8" 23 "Reserved_9" 24 "Reserved_10" 25 "Reserved_11" 26 "Reserved_12" 27 "Reserved_13" 28 "Reserved_14" 29 "Reserved_15" 30 "Reserved_16" 31 "Req_TLC" ;
VAL_ 513 HPPDriverOperateIndFrmADD 0 "No_Request" 1 "LearnOpr_HighSpeed" 2 "LearnOpr_DistanceOutOfLimit" 3 "LearnOpr_PathRepeated" 4 "LearnOpr_RuleBroke" 5 "LearnOpr_StudyOverTime" 6 "LearnOpr_ParkingOverTime" 7 "LearnOpr_DriverSeatBeltNotTied" 8 "LearnOpr_IfParkingBrakeChooseSlot" 9 "LearnOpr_BrakeFirstChooseSlot" 10 "LearnOpr_NoParkingSlot" 11 "LearnOpr_ChooseParkingSlotFirst" 12 "LearnOpr_RDistanceOutOfLimit" 13 "PlayBackOpr_NoResponse_gas_pedal" 14 "PlayBackOpr_NoResponseTurnlight" 15 "PlayBackOpr_NoResponseGearShift" 16 "PlyBakOpr_Recover_DoorOpen" 17 "PlyBakOpr_Recover_EngineFrontDoorOpen" 18 "PlyBakOpr_Recover_TrunkOpen" 19 "PlyBakOpr_Recover_DriverSeatBeltNotTied" 20 "PlyBakOpr_Recover_Obstaclesblocktraffic" 21 "PlayBackOpr_BrakeFirstChooseSlot" 22 "PlayBackOpr_ObstructAcs_Takeover" 23 "Reserved_1" 24 "Reserved_2" 25 "Reserved_3" 26 "Reserved_4" 27 "Reserved_5" 28 "Reserved_6" 29 "Reserved_7" 30 "Reserved_8" 31 "Req_TLC" ;
VAL_ 513 HPPIcnDispStsFrmADD 0 "no_display" 1 "grey" 2 "light" 3 "yellow_unable_active" 4 "yellow_system_failure" 5 "learning" 6 "reserved" 7 "reserved" ;
VAL_ 513 HPPInfotipFrmADD 0 "None" 1 "Learn_StartLearningPleaseDrive" 2 "Learn_RoutelearningProcess" 3 "Learn_SpeedBump" 4 "Learn_CrossRoad" 5 "Learn_Ramp" 6 "Learn_ManualParkingProcess" 7 "PlyBak_ThroughGateMachine" 8 "PlyBak_Turningleft" 9 "PlyBak_TurningRight" 10 "PlyBak_SpeedBump" 11 "PlyBak_CrossRoad" 12 "PlyBak_Ramp" 13 "PlyBak_Willcar" 14 "PlyBak_WarningVru" 15 "PlyBak_WarningObstacle" 16 "PlyBak_DetourObstacle" 17 "PlyBak_StartPlyBak_Recommend(Start)" 18 "PlyBak_NearTarParkSlot" 19 "PlyBak_NearTarLocn" 20 "PlyBak_BackMapFindParkingSlot" 21 "PlyBak_WillAPAParkIn_FixSlot" 22 "PlyBak_WillAPAParkIn_PrferceZone" 23 "PlyBak_Completed" 24 "PlyBak_StartPlyBak_Recommend(Start)_Allline" 25 "PlyBak_PlyBakProcess_Recommend_FixSlot_PrferceZone" 26 "PlyBak_PlyBakProcess_Recommend_AllLine" 27 "PlyBak_StartPlyBak_Recommend(Start)_AVPRoam" 28 "PlyBak_PlyBakProcess_Recommend_AVPRoam" 29 "Reserved_3" 30 "Reserved_4" 31 "Reserved_5" 32 "Reserved_6" 33 "Reserved_7" 34 "Reserved_8" 35 "Reserved_9" 36 "Reserved_10" 37 "Reserved_11" 38 "Reserved_12" 39 "Reserved_13" 40 "Reserved_14" 41 "Reserved_15" 42 "Reserved_16" 43 "Reserved_17" 44 "Reserved_18" 45 "Reserved_19" 46 "Reserved_20" 47 "Reserved_21" 48 "Reserved_22" 49 "Reserved_23" 50 "Reserved_24" 51 "Reserved_25" 52 "Reserved_26" 53 "Reserved_27" 54 "Reserved_28" 55 "Reserved_29" 56 "Reserved_30" 57 "Reserved_31" 58 "Reserved_32" 59 "Reserved_33" 60 "Reserved_34" 61 "Reserved_35" 62 "Reserved_36" 63 "Req_TLC" ;
VAL_ 513 HPPLearnSubStsFrmADD 0 "Learnpassive" 1 "Standby" 2 "Crusing" 3 "ManualParking" 4 "APA" 5 "Completed" 6 "Confirmation" 7 "Terminated" 8 "Waiting" 9 "Save" 10 "Failure" ;
VAL_ 513 HPPLrnVcFbFrmADD 0 "NotLearning" 1 "Learning" ;
VAL_ 513 HPPPlayBackPushFrmADD 0 "No_Request" 1 "RecommendUseHPPPlayBack" ;
VAL_ 513 HPPQuitIndFrmADD 0 "No_Request" 1 "LearnQuit_SpeedOutOfLimit" 2 "LearnQuit_longRoute" 3 "LearnQuit_RouteRepeat" 4 "LearnQuit_OverTime" 5 "LearnQuit_UP&DownSlope" 6 "LearnQuit_OverlapTooComplex" 7 "LearnQuit_SystemFailure" 8 "LearnQuit_SlopeOutOfLimit" 9 "LearnQuit_HVSocLow" 10 "LearnQuit_DoorOpen" 11 "LearnQuit_FrontLidOpen" 12 "LearnQuit_RearLidOpen" 13 "LearnQuit_EnvimntEmpty" 14 "LearnQuit_AVMNotOnline" 15 "LearnQuit_RDistanceOutOfLimit" 16 "LearnQuit_DriveInRamp" 17 "LearnQuit_Charging" 18 "LearnQuit_ADAS_Function_Active" 19 "LearnQuit_OtherReason" 20 "PlayBack_SpeedOutofLimit" 21 "PlayBack_GearsShifted" 22 "PlayBack_ParkingOverTime" 23 "PlayBack_ReplayOverTime" 24 "PlayBack_PauseOverTime" 25 "PlayBack_DoorOpen" 26 "PlayBack_FrontLidOpen" 27 "PlayBack_RearLidOpen" 28 "PlayBack_PositionLost" 29 "PlayBack_HVSocLow" 30 "PlayBack_APATerminated" 31 "PlayBack_SystemMalFunction" 32 "PlayBack_EnviromentDisallowed" 33 "PlayBack_SpecialDrivingMode" 34 "PlayBack_BrakingPedalStepped" 35 "PlayBack_SteeringWheelSteered" 36 "PlayBack_OutODD" 37 "PlayBack_DriverQuit" 38 "PlayBack_P" 39 "PlayBack_Charging" 40 "PlayBack_ADAS_Function_Active" 41 "PlayBack_NoParkingSlot" 42 "PlayBack_OtherReason" 43 "PlayBack_RoamCalculateFailed" 44 "PlayBack_NoParkingSlot_Fuzzy" 45 "Reserved_3" 46 "Reserved_4" 47 "Reserved_5" 48 "Reserved_6" 49 "Reserved_7" 50 "Reserved_8" 51 "Reserved_9" 52 "Reserved_10" 53 "Reserved_11" 54 "Reserved_12" 55 "Reserved_13" 56 "Reserved_14" 57 "Reserved_15" 58 "Reserved_16" 59 "Reserved_17" 60 "Reserved_18" 61 "Reserved_19" 62 "Reserved_20" 63 "Reserved_21" 64 "Reserved_22" 65 "Reserved_23" 66 "Reserved_24" 67 "Reserved_25" 68 "Reserved_26" 69 "Reserved_27" 70 "Reserved_28" 71 "Reserved_29" 72 "Reserved_30" 73 "Reserved_31" 74 "Reserved_32" 75 "Reserved_33" 76 "Reserved_34" 77 "Reserved_35" 78 "Reserved_36" 79 "Reserved_37" 80 "Reserved_38" 81 "Reserved_39" 82 "Reserved_40" 83 "Reserved_41" 84 "Reserved_42" 85 "Reserved_43" 86 "Reserved_44" 87 "Reserved_45" 88 "Reserved_46" 89 "Reserved_47" 90 "Reserved_48" 91 "Reserved_49" 92 "Reserved_50" 93 "Reserved_51" 94 "Reserved_52" 95 "Reserved_53" 96 "Reserved_54" 97 "Reserved_55" 98 "Reserved_56" 99 "Reserved_57" 100 "Reserved_58" 101 "Reserved_59" 102 "Reserved_60" 103 "Reserved_61" 104 "Reserved_62" 105 "Reserved_63" 106 "Reserved_64" 107 "Reserved_65" 108 "Reserved_66" 109 "Reserved_67" 110 "Reserved_68" 111 "Reserved_69" 112 "Reserved_70" 113 "Reserved_71" 114 "Reserved_72" 115 "Reserved_73" 116 "Reserved_74" 117 "Reserved_75" 118 "Reserved_76" 119 "Reserved_77" 120 "Reserved_78" 121 "Reserved_79" 122 "Reserved_80" 123 "Reserved_81" 124 "Reserved_82" 125 "Reserved_83" 126 "Reserved_84" 127 "Req_TLC" ;
VAL_ 513 HPPRecoverButtonStsFrmADD 0 "Default" 1 "Passive" 2 "Standby" ;
VAL_ 513 HPPRecoverIndFrmADD 0 "No_Request" 1 "RecvInd_AvodingPedestrains" 2 "RecvInd_AvodingObstacles" 3 "RecvInd_Reversing" 4 "RecvInd_Crossing" 5 "RecvInd_APARequest" 6 "RecvInd_CP_Overtake_Req" 7 "RecvInd_ParkingSpaceOccupied" 8 "RecvInd_TakeOverSteeringWheelRequest" 9 "RecvInd_SelectSpaceAfterBraking" 10 "RecvInd_SapceOccupiedGo2NewSpace" 11 "RecvInd_BrakingPedalStepped" 12 "RecvInd_BrakePedal&SteeringWheelControlled" 13 "RecvInd_GearsShifted" 14 "RecvInd_ObstaclesInterrupted" 15 "RecvInd_GateMachineInterrupted" 16 "RecvInd_ParkingLocked" 17 "RecvInd_GasPedalStepped" 18 "RecvInd_SteeringWheelControlled" 19 "RecvInd_GasPedal&SteeringWheelControlled" ;
VAL_ 513 HPPRouteInd2FrmADD 0 "No_Request" 1 "RouteSavedSucceed" 2 "RoutePreferenceSetSucceed" 3 "RouteSavingProcess" 4 "RouteShareSucceed" 5 "DeleteRouteSucceed" 6 "RouteDownloaded" 7 "RenameSucceed" 8 "Reserved_1" 9 "Reserved_2" 10 "Reserved_3" 11 "Reserved_4" 12 "Reserved_5" 13 "Reserved_6" 14 "Reserved_7" 15 "Req_TLC" ;
VAL_ 513 HPPRouteIndFrmADD 0 "No_Request" 1 "RouteSaveFailed" 2 "RouteSaveFailed_Long" 3 "RouteSaveFailed_FewFeature" 4 "RouteSaveFailed_LargeRepetition" 5 "RouteSaveFailed_HighSpeed" 6 "RouteSaveFailed_SystemFailure" 7 "RouteShareFailure" 8 "DeleteRouteFailed" 9 "RouteDownloadFailed" 10 "Renamefailed" 11 "RoutePreferenceSetFailed" 12 "Reserved_1" 13 "Reserved_2" 14 "Reserved_3" 15 "Reserved_4" 16 "Reserved_5" 17 "Reserved_6" 18 "Reserved_7" 19 "Reserved_8" 20 "Reserved_9" 21 "Reserved_10" 22 "Reserved_11" 23 "Reserved_12" 24 "Reserved_13" 25 "Reserved_14" 26 "Reserved_15" 27 "Reserved_16" 28 "Reserved_17" 29 "Reserved_18" 30 "Reserved_19" 31 "Req_TLC" ;
VAL_ 513 HPPRouteManageStsFrmADD 0 "Abnormal" 1 "Normal" ;
VAL_ 513 HPPUnableToActiveIndFrmADD 0 "No_Request" 1 "UnabLern_Charging" 2 "UnabLern_Go_groundThenDown" 3 "UnabLern_HVSocLow" 4 "UnabLern_BadWeather" 5 "UnabLern_SlopeOutOfLimit" 6 "UnabLern_SystemFailure" 7 "UnabLern_Specialcase" 8 "UnabLern_OutOfCarpark" 9 "UnabLern_Lowpower_mode" 10 "UnabLern_Extreme_eco_mode" 11 "UnabLern_Privacy_mode" 12 "UnabLern_Trailermode" 13 "UnabLern_Rescue_mode" 14 "UnabLern_Tire_change_mode" 15 "UnabLern_Ejector_mode" 16 "UnabLern_Wash_mode" 17 "UnabLern_Snow_mode" 18 "UnabLern_Battle_mode" 19 "UnabLern_Mountain_mode" 20 "UnabLern_Drift_mode" 21 "UnabLern_Setting_option_blocked" 22 "UnabLern_ADAS_Function_Active" 23 "UnabLern_DoorOpen" 24 "UnabLern_FrontLidOpen" 25 "UnabLern_RearLidOpen" 26 "UnabLern_Oth_ODD_Cdn_NotMet" 27 "UnabLern_LidarSysBlkd" 28 "UnabLern_SVSSysBlkd" 29 "UnabLern_HighSpeed" 30 "UnabLern_SSB" 31 "UnabLern_OtherReaon" 32 "UnabPlyBak_Charging" 33 "UnabPlyBak_SpeedOutOfLimit" 34 "UnabPlyBak_DepartureMismatch" 35 "UnabPlyBak_PublicRoad" 36 "UnabPlyBak__HVSocLow" 37 "UnabPlyBak_BadWeather" 38 "UnabPlyBak_SlopeOutOfLimit" 39 "UnabPlyBak_SpecialDrivingMode" 40 "UnabPlyBak_SystemFailure" 41 "UnabPlyBak_NoRouteAvailable" 42 "UnabPlyBak_LargeSWA" 43 "UnabPlyBak_Extreme_eco_mode" 44 "UnabPlyBak_Privacy_mode" 45 "UnabPlyBak_Trailermode" 46 "UnabPlyBak_Rescue_mode" 47 "UnabPlyBak_Tire_change_mode" 48 "UnabPlyBak_Ejector_mode" 49 "UnabPlyBak_Wash_mode" 50 "UnabPlyBak_Snow_mode" 51 "UnabPlyBak_Battle_mode" 52 "UnabPlyBak_Mountain_mode" 53 "UnabPlyBak_Drift_mode" 54 "UnabPlyBak_Setting_option_blocked" 55 "UnabPlyBak_SeatBeltNotBuckled" 56 "UnabPlyBak_DoorOpen" 57 "UnabPlyBak_FrontLidOpen" 58 "UnabPlyBak_RearLidOpen" 59 "UnabPlyBak_DrvrNotOcuped" 60 "UnabPlyBak_ESPOff" 61 "UnabPlyBak_CarInSlot" 62 "UnabPlyBak_CloseToEndAndNoSlot" 63 "UnabPlyBak_Oth_ODD_Cdn_NotMet" 64 "UnabPlyBak_ADAS_Function_Active" 65 "UnabPlyBak_LidarSysBlkd" 66 "UnabPlyBak_SVSSysBlkd" 67 "UnabPlyBak_SideCamSysBlkd" 68 "UnabPlyBak_FrontCamSysBlkd" 69 "UnabPlyBak_RearCamSysBlkd" 70 "UnabPlyBak_lowpower_mode" 71 "UnabPlyBak_SSB" 72 "UnabPlyBak_OtherReaon" 73 "UnabPlyBak_NoNavigationPaths" 74 "UnabPlyBak_INNavigationPathsCalculating" 75 "UnabLern_INAVPCarpark" 76 "UnabPlyBak_HPP_Learning_Try_Later" 77 "UnabPlyBak_Suspension_Adjusted_Try_Later" 78 "UnabPlyBak_HPP_Uavailable_Try_Later" 79 "UnabPlyBak_Function_Unavailable_Temporary" 80 "UnabPlyBak_D_Gear_Please" 81 "UnabPlyBak_Vehicle_Mode_Abnormal" 82 "R_10" 83 "R_11" 84 "R_12" 85 "R_13" 86 "R_14" 87 "R_15" 88 "R_16" 89 "R_17" 90 "R_18" 91 "R_19" 92 "R_20" 93 "R_21" 94 "R_22" 95 "R_23" 96 "R_24" 97 "R_25" 98 "R_26" 99 "R_27" 100 "R_28" 101 "R_29" 102 "R_30" 103 "R_31" 104 "R_32" 105 "R_33" 106 "R_34" 107 "R_35" 108 "R_36" 109 "R_37" 110 "R_38" 111 "R_39" 112 "R_40" 113 "R_41" 114 "R_42" 115 "R_43" 116 "R_44" 117 "R_45" 118 "R_46" 119 "R_47" 120 "R_48" 121 "R_49" 122 "R_50" 123 "R_51" 124 "R_52" 125 "R_53" 126 "R_54" 127 "Req_TLC" ;
VAL_ 513 HPPVehInParkSlotFrmADD 0 "OutParkslot" 1 "InParkslot" ;
VAL_ 513 IMUStsFrmADD 0 "normal" 1 "PerformanceDegradation" 2 "blocked" 3 "Error" 4 "Reserved" ;
VAL_ 513 LidarStsFrmADD 0 "Not_Blocked" 1 "Left_Lidar_Blocked" 2 "Right_Lidar_Blocked" 3 "Both_Blocked" ;
VAL_ 513 ParkVicShdFrmADD 0 "No_Inhibit" 1 "APA_Inhibit" 2 "RPA_Inhibit" 3 "HPP_Inhibit" 4 "AVP_Inhibit" 5 "Reserved" 6 "Reserved" 7 "Reserved" ;
VAL_ 513 PrkSteerWhlBtnLi 0 "No_Request" 1 "Request_breathe_Light" 2 "Reserved" 3 "Reserved" ;
VAL_ 513 ReCamStsFrmADD 0 "off" 1 "Standby" 2 "Normal" 3 "Blocked" 4 "Error" 5 "Reserved" 6 "Reserved" 7 "Reserved" ;
VAL_ 513 ReDVRStsFrmADD 0 "Idle" 1 "DVR_service_is_available" 2 "camera_is_not_available" 3 "processing_resource_is_not_available" 4 "connection_is_not_available" 5 "reserved" 6 "reserved" 7 "reserved" ;
VAL_ 513 RUSSStsFrmADD 0 "normal" 1 "blocked" 2 "Error" 3 "Reserved" ;
VAL_ 513 SLFCamStsFrmADD 0 "off" 1 "Standby" 2 "Normal" 3 "Blocked" 4 "Error" 5 "Reserved" 6 "Reserved" 7 "Reserved" ;
VAL_ 513 SLFDVRStsFrmADD 0 "Idle" 1 "DVR_service_is_available" 2 "camera_is_not_available" 3 "processing_resource_is_not_available" 4 "connection_is_not_available" 5 "reserved" 6 "reserved" 7 "reserved" ;
VAL_ 513 SLLidarStsFrmADD 0 "normal" 1 "PerformanceDegradation" 2 "blocked" 3 "Error" 4 "Reserved" ;
VAL_ 513 SLRCamStsFrmADD 0 "off" 1 "Standby" 2 "Normal" 3 "Blocked" 4 "Error" 5 "Reserved" 6 "Reserved" 7 "Reserved" ;
VAL_ 513 SLRDVRStsFrmADD 0 "Idle" 1 "DVR_service_is_available" 2 "camera_is_not_available" 3 "processing_resource_is_not_available" 4 "connection_is_not_available" 5 "reserved" 6 "reserved" 7 "reserved" ;
VAL_ 513 SnmDetResFrmADD 0 "idle" 1 "Normal" 2 "Abnormal" 3 "Danger" ;
VAL_ 513 SnmF120CamDetResFrmADD 0 "idle" 1 "Normal" 2 "Abnormal" 3 "Danger" ;
VAL_ 513 SnmReCamDetResFrmADD 0 "idle" 1 "Normal" 2 "Abnormal" 3 "Danger" ;
VAL_ 513 SnmSLFCamDetResFrmADD 0 "idle" 1 "Normal" 2 "Abnormal" 3 "Danger" ;
VAL_ 513 SnmSLRCamDetResFrmADD 0 "idle" 1 "Normal" 2 "Abnormal" 3 "Danger" ;
VAL_ 513 SnmSRFCamDetResFrmADD 0 "idle" 1 "Normal" 2 "Abnormal" 3 "Danger" ;
VAL_ 513 SnmSRRCamDetResFrmADD 0 "idle" 1 "Normal" 2 "Abnormal" 3 "Danger" ;
VAL_ 513 SRFCamStsFrmADD 0 "off" 1 "Standby" 2 "Normal" 3 "Blocked" 4 "Error" 5 "Reserved" 6 "Reserved" 7 "Reserved" ;
VAL_ 513 SRLidarStsFrmADD 0 "normal" 1 "PerformanceDegradation" 2 "blocked" 3 "Error" 4 "Reserved" ;
VAL_ 513 SRRCamStsFrmADD 0 "off" 1 "Standby" 2 "Normal" 3 "Blocked" 4 "Error" 5 "Reserved" 6 "Reserved" 7 "Reserved" ;
VAL_ 513 SRRDVRStsFrmADD 0 "Idle" 1 "DVR_service_is_available" 2 "camera_is_not_available" 3 "processing_resource_is_not_available" 4 "connection_is_not_available" 5 "reserved" 6 "reserved" 7 "reserved" ;
VAL_ 516 APAAlrtWarnFrmADD 0 "No_Request" 1 "TakeOverWarnRequest" 2 "Reserved" 3 "Reserved" ;
VAL_ 516 APAButtonReqFrmADD 0 "No_Request" 1 "ParkIn_Request" 2 "ParkOut_Request" 3 "Reserved" ;
VAL_ 516 APARPAActiveSubFunFrmADD 0 "None" 1 "APA_Park_in" 2 "APA_Park_Out" 3 "RPA_Park_in" 4 "RPA_Park_Out" 5 "RPA_Move" ;
VAL_ 516 APARPADriverOperateInd2FrmADD 0 "No_Request" 1 "Search_Choose_Parkslot_Speed_Not_Zero" 2 "Act_NarrowSlot_Mirrors_folding" 3 "Act_No_Response_gaspedal" 4 "Act_No_Response_Steeringlight" 5 "Act_No_Response_GearPaddle" 6 "Act_More_Trajectory_Mode" 7 "Recover_brake_pedal" 8 "Recover_Door_Open" 9 "Recover_FrontLidOpen" 10 "Recover_RearLidOpen" 11 "Warning_DriverControl" 12 "Recover_obstacle" 13 "Search_Door_Open" 14 "Search_FrontLidOpen" 15 "Search_Recover_RearLidOpen" 16 "Recover_DrvrNotOcupcy" 17 "Search_Speed_high" 18 "Search_NarrowSlot_Recommend_RPA" 19 "Tips_Return_APA" 20 "Act_Start_parking_Recommend(Release_steerwheel&Brake)" 21 "Parking_Completed" 22 "Parking_Completed_Stereo_Lot" 23 "Act_ParkOut_ExtMirr_Fold" 24 "Act_ParkOut_ExtMirr_Unfold" 25 "ParkOut_Completed" 26 "Act_Air_Suspension_Control" 27 "OutDoorParkinTips" 28 "Reserved_8" 29 "Reserved_9" 30 "Reserved_10" 31 "Reserved_11" 32 "Reserved_12" 33 "Reserved_13" 34 "Reserved_14" 35 "Reserved_15" 36 "Reserved_16" 37 "Reserved_17" 38 "Reserved_18" 39 "Reserved_19" 40 "Reserved_20" 41 "Reserved_21" 42 "Reserved_22" 43 "Reserved_23" 44 "Reserved_24" 45 "Reserved_25" 46 "Reserved_26" 47 "Reserved_27" 48 "Reserved_28" 49 "Reserved_29" 50 "Reserved_30" 51 "Reserved_31" 52 "Reserved_32" 53 "Reserved_33" 54 "Reserved_34" 55 "Reserved_35" 56 "Reserved_36" 57 "Reserved_37" 58 "Reserved_38" 59 "Reserved_39" 60 "Reserved_40" 61 "Reserved_41" 62 "Reserved_42" 63 "Req_TLC" ;
VAL_ 516 APARPADriverOperateIndFrmADD 0 "No_Request" 1 "Req_Gear_D" 2 "Req_Slow_Down" 3 "Req_Close_Door_Driver" 4 "Req_Close_Door_passenger" 5 "Req_Close_Door_LeftRear" 6 "Req_Close_Door_RightRear" 7 "Req_Close_Engine_Front_Door" 8 "Req_Close_Trunk" 9 "Req_Parking_slot_in_Searching" 10 "Req_ParkOut_is_Available" 11 "Req_Parking_Process_Recommend(PI&PO)_stereo_lot_ARS" 12 "Req_Choose_Park_Slot" 13 "Req_Click_Start_ParkOut_Button" 14 "Req_Parking_Process_Recommend(PI&PO)__stereo_lot" 15 "Req_Choose_Park_out_direction" 16 "Req_Click_Start_APA_park_Button" 17 "Req_Start_parking_Recommend(Release_steerwheel&Brake)" 18 "Req_Parking_process_Recommend(PI&PO)" 19 "Req_Choose_ParkOut_Direction_Speed_Not_Zero" 20 "Req_ParkOut_Gear_D_or_R" 21 "Req_ParkOut_No_Direction" 22 "Req_Leave_car_Control_on_APP" 23 "Req_ParkOut_Direction_Available" 24 "Req_ParkOut_Process_Recommend(PI&PO)_Left" 25 "Req_ParkOut_Process_Recommend(PI&PO)_Right" 26 "Req_ParkOut_ExtMirr_Fold" 27 "Req_ParkOut_ExtMirr_Unfold" 28 "Req_Self_check_RPA_park_out/move__avaiable" 29 "Req_Self_check_only_RPA_move_avaiable" 30 "Req_Close_Door_LeftRear_RPA" 31 "Req_Close_Door_RightRear_RPA" 32 "Req_Close_Engine_Front_Door_RPA" 33 "Req_Close_Trunk_RPA" 34 "Req_RPA_move_completed" 35 "Req_Pop-ups_Choose_system_refence_Parking_Slot" 36 "Req_Keep_Standstill" 37 "Not_P_Gear" 38 "Req_Press_Button_Not_Press_Brakepedal" 39 "Req_Press_Button_N0_Parkslot" 40 "Req_Press_Brakepedal_Parkslot_Exist" 41 "Req_Left_AutoDeviation_APA" 42 "Req_Right_AutoDeviation_APA" 43 "Parking_GearChange_NotAllow" 44 "AD_NotAvl" 45 "Req_Choose_Parkslot_Speed_Not_Zero" 46 "Recom_Narrow" 47 "Choose_ps" 48 "RPAselfcheck" 49 "RPA_move_selfcheck" 50 "No_parking_record" 51 "Can_not_move" 52 "one_button_search" 53 "one_button_bckgrd" 54 "one_button_parking" 55 "Reserved_1" 56 "Reserved_2" 57 "Reserved_3" 58 "Reserved_4" 59 "Reserved_5" 60 "Reserved_6" 61 "Reserved_7" 62 "Reserved_8" 63 "Req_TLC" ;
VAL_ 516 APARPAQuitReasonIndFrmADD 0 "No_Request" 1 "Req_Quit_Searching_Speed_High" 2 "Req_Quit_Searching_Time_Out" 3 "Req_Quit_HDCmode" 4 "Req_Quit_Door_Open_Time_Out" 5 "Req_Quit_Handshake_Fail" 6 "Req_Quit_Driver_Require_Quit" 7 "Req_Quit_Driver_Not_release_Brake_Pedal_Time_Out" 8 "Req_Quit_DriverSeatBelt_Nottied_Time_Out" 9 "Req_Quit_ParkOut_Leave_storage" 10 "Rear_Spoiler_Not_P0" 11 "Req_Quit_Driver_Interrupt_Brake_Pedal_Time_Out" 12 "Req_Quit_Driver_Interrupt_Gear" 13 "Req_Quit_Driver_Interrupt_Steering_Wheel" 14 "Req_Quit_Obstacle_In_Trajectory_Time_Out" 15 "Req_Quit_EPB_UnLock" 16 "Req_Quit_Parking_Total_time_Time_Out" 17 "Req_Quit_Recover_Interrupt_Times_Overflow" 18 "Req_Quit_D/R_Times_Overflow" 19 "Req_Quit_Control_Speed_Over_Limit" 20 "Req_Quit_Path_Planning_Abnormal" 21 "APP_Quit_RPAin" 22 "Req_Quit_Slope_Out_Of_limit" 23 "Req_Quit_ADAS_Function_Active" 24 "Req_Quit_Parking_Total_time_TimeOut_RPA" 25 "Req_Quit_Slope_Out_of_limit_RPA" 26 "Req_Quit_ADD_System_Fail" 27 "Req_Quit_ADD_System_Fail_RPA" 28 "Blue_Tooth_Connect_UnStable_Timeout_RPA_In" 29 "Account_log_out" 30 "Req_Quit_ADAS_Function_Active_RPA" 31 "Blue_Tooth_Connect_UnStable_Timeout_RPA_Move" 32 "Req_Quit_Active_Rear_Spoiler_Not_P0" 33 "Req_Quit_Driver_leave_Phone_RPA_Contro_lPage_Time_Out(RPA)" 34 "APP_Quit_RPA_Move" 35 "Req_Driver_Interrupt_RPA_In" 36 "Req_Driver_Interrupt_RPA_Move" 37 "Req_Quit_Driver_Interrupt_Press_Gas_Pedal(RPA)" 38 "Req_Quit_Driver_Interrupt_Press_Brake_Pedal(RPA)" 39 "Battery_Low_RPA_Move" 40 "Req_Quit_Handshake_Fail_RPA_Move" 41 "Req_Quit_Total_Distance_overrange(RPA_Move)" 42 "Req_Quit_Warning_someone_In_car_Time_Out(RPA)" 43 "Req_Quit_Control_Speed_Over_Limit_RPA_Move" 44 "Req_Quit_Narrow_Slot_RPA_In" 45 "Req_Quit_Timeout_Not_Press_Start_Button(RPA)" 46 "Req_Quit_Stereo_Lot_Narrow" 47 "Req_Quit_Function_off" 48 "BatteryLow" 49 "Req_Quit_Driver_Interrupt_Gear_RPA" 50 "Req_Quit_Driver_Door_Open" 51 "Plannig_Control_Sleep" 52 "Req_Quit_MirrorFold_Fail_RPA" 53 "Req_Quit_MirrorFold_Fail" 54 "Req_Quit_Obstacle_In_Trajectory_TimeOut_RPA_Move" 55 "CounterAbnormal_TimeOut_RPA_In" 56 "CounterAbnormal_TimeOut_RPA_Move" 57 "CRC_Abnormal_RPA_In" 58 "CRC_Abnormal_RPA_Move" 59 "FrontLid_Open_TimeOut" 60 "RearLid_Open_TimeOut" 61 "Req_Quit_OtherReason" 62 "Plannig_Control_Sleep_RPA_Move" 63 "Controller_Abnormal_RPA_Move" ;
VAL_ 516 APARPARecoverIndFrmADD 0 "No_Request" 1 "Req_Recover_DriverSeatBeltNot_tied" 2 "Req_Recover_ParkOut_ExtMirr_Fold" 3 "Req_Recover_Found_Obstacle_In_Trajectory" 4 "Req_Recover_Phone_out_of_range" 5 "Req_Recover_Driver_Press_brake_pedal" 6 "Req_Recover_DoorOpen_Driver" 7 "Req_Recover_DoorOpen_passenger" 8 "Req_Recover_DoorOpen_LeftRear" 9 "Req_Recover_DoorOpen_RightRear" 10 "Req_Recover_Engine_Front_DoorOpen" 11 "Req_Recover_TrunkOpen" 12 "Req_Recover_DoorOpen_RPA" 13 "Req_Recover_Engine_Front_DoorOpen_RPA" 14 "Req_Recover_TrunkOpen_RPA" 15 "Req_Recover_RPA_Move_Driver_Active_pause" 16 "Req_DrvrNotOcupcy" 17 "Pause_To_Active" 18 "CounterAbnormal_RPA_in" 19 "CounterAbnormal_RPA_Move" 20 "Recover_Blue_Tooth_Connect_UnStable_RPA_In" 21 "Recover_Blue_Tooth_Connect_UnStable_RPA_Move" 22 "Reserved_3" 23 "Reserved_4" 24 "Reserved_5" 25 "Reserved_6" 26 "Reserved_7" 27 "Reserved_8" 28 "Reserved_9" 29 "Reserved_10" 30 "Reserved_11" 31 "Lev_Control_Page" ;
VAL_ 516 APARPAstatusFrmADD 0 "Off" 1 "Standby" 2 "background_Searching" 3 "Searching" 4 "Ready" 5 "Active" 6 "Recovery_interrupt" 7 "Completed" 8 "Terminated" 9 "Failure" ;
VAL_ 516 APARPAUnableToActiveIndFrmADD 0 "No_Request" 1 "Speed_high" 2 "Slope_out_of_limit" 3 "Charging" 4 "ADAS_Function_Active" 5 "Speed_ParkOut_Voice" 6 "Not_in_Parking_Space_ParkOut_Voice" 7 "ImpctEvnt_or_ACUWarn_APA" 8 "ParkOut_Stereo_Lot" 9 "Air_suspension_Action" 10 "Low_Power_Mode" 11 "Extreme_Economic_Driving_Mode" 12 "One-click_Privacy_Enable" 13 "Trailer_Mode" 14 "Car_Wash_Mode" 15 "AD_Setting_Not_Enable" 16 "ESC_Off" 17 "ODD_Not_Available" 18 "Driver_Door_Open" 19 "NO_Detailed_Reason_Failure" 20 "Rescue_Mode" 21 "Tire_Change_Mode" 22 "Ejection_Mode" 23 "Snow_Mode" 24 "One-click_Frenzy_Mode" 25 "Track_Mode" 26 "Drift_Mode" 27 "PwrModSts_NotRun" 28 "RPA2APA" 29 "Lidar_Blocked" 30 "SVS_Blocked" 31 "Drv_Mod_Unable_APA" 32 "Drg_Rac_Mode_Active_APA" 33 "Off_Road_Active_APA" 34 "HDC_Mode_Active_APA" 35 "Mountain_Mode_Active_APA" 36 "AntMtnsick_Mode_Active_APA" 37 "Controller_Sleep_RPAmove" 38 "Door_Open_RPA" 39 "FrontLidOpen_RPA" 40 "RearLidOpen_RPA" 41 "SVS_Blocked_Blur" 42 "Account_not_log_in" 43 "Not_P" 44 "Obstacle_RPA" 45 "someone_in_car" 46 "DR_Abnormal_APA" 47 "DR_Abnormal_RPAmove" 48 "System_failure_APA" 49 "ExtmPfmncMod_RPAmove" 50 "Rescue_Mode_RPAmove" 51 "OtherReason" 52 "Speed_Not_Zero_RPAMove" 53 "Low_Pwrmod_RPAMove" 54 "ADAS_Active_RPAMove" 55 "Slope_out_of_limit_RPAMove" 56 "Privacy_Mode_RPAMove" 57 "Trlr_Mode_RPAMove" 58 "Jack_Mode_RPAMove" 59 "Lnch_Plus_RPAMove" 60 "Snow_Mode_RPAMove" 61 "Mountain_Mode_RPAMove" 62 "Battle_Mode_RPAMove" 63 "Extreme_Eco_Mode_RPAMove" ;
VAL_ 516 AVPCharLidCtrlFrmADD 0 "No_Request" 1 "OpenLid" 2 "CloseLid" 3 "Reserved" ;
VAL_ 516 DriverlessStsFrmADD 0 "None" 1 "Driverless_Active" 2 "Reserved_1" 3 "Reserved_2" ;
VAL_ 516 OutdoorPrkDrvrOperIndFrmADD 0 "None" 1 "Req_Close_Door_Driver_RPAmove" 2 "Req_Close_Door_passenger_RPAmove" 3 "Req_Close_Door_Driver_RPAin" 4 "Req_Close_Door_passenger_RPAin" 5 "Req_Close_Door_LeftRear_RPAin" 6 "Req_Close_Door_RightRear_RPAin" 7 "Req_Close_Engine_Front_Door_RPAin" 8 "Req_Close_Trunk_RPAin" 9 "Req_Warning_someone_In_car_RPAmove" 10 "Searching_Lev_Control_Page_RPAin" 11 "Found_Obstacle_In_Trajectory_RPAin" 12 "Reserved_1" 13 "Blue_Tooth_Connect_UnStable_RPAin" 14 "Reserved_2" 15 "Reserved_3" 16 "Reserved_4" 17 "Reserved_5" 18 "Reserved_6" 19 "Blue_Tooth_Connect_UnStable_RPA_Move" 20 "Reserved_7" 21 "Reserved_8" 22 "Reserved_9" 23 "Reserved_10" 24 "Reserved_11" 25 "Req_Warning_someone_In_car_RPAin" 26 "Reserved_12" 27 "Reserved_13" 28 "Reserved_14" 29 "Reserved_15" 30 "Req_Close_Door_LeftRear_RPAmove" 31 "Req_Close_Door_RightRear_RPAmove" 32 "Req_Close_Engine_Front_Door_RPAmove" 33 "Req_Close_Trunk_RPAmove" 35 "Reserved_16" 36 "Reserved_17" 37 "Reserved_18" 38 "Reserved_19" 39 "Reserved_20" 40 "Reserved_21" 41 "Reserved_22" 42 "Reserved_23" 43 "Reserved_24" 44 "Reserved_25" 45 "Reserved_26" 46 "Reserved_27" 47 "Reserved_28" 48 "Reserved_29" 49 "Reserved_30" 50 "Reserved_31" 51 "Reserved_32" 52 "Reserved_33" 53 "Reserved_34" 54 "Reserved_35" 55 "Reserved_36" 56 "Reserved_37" 57 "Reserved_38" 58 "Reserved_39" 59 "Reserved_40" 60 "Reserved_41" 61 "Reserved_42" 62 "Reserved_43" 63 "Reserved_44" ;
VAL_ 516 OutdoorPrkQuitIndFrmADD 0 "None" 1 "FrontLid_Open_TimeOut_RPAmove" 2 "RearLid_Open_TimeOut_RPAmove" 3 "Req_Quit_Door_Open_Time_Out_RPAmove" 4 "Req_Quit_Door_Open_Time_Out_RPAin" 5 "Req_Quit_Handshake_Fail_RPAin" 6 "Req_Quit_Warning_someone_In_car_Time_Out_RPAmove" 7 "Req_Quit_Timeout_Not_Press_Start_Button_RPAmove" 8 "Reserved_1" 9 "Req_Quit_Driver_Interrupt_Steering_Wheel_RPAmove" 10 "Reserved_2" 11 "Reserved_3" 12 "Req_Quit_Driver_Interrupt_Gear_RPAin" 13 "Req_Quit_Driver_Interrupt_Steering_WheelRPAin" 14 "Req_Quit_Obstacle_In_Trajectory_Time_Out_RPAin" 15 "Reserved_4" 16 "Req_Quit_Parking_Total_time_Time_Out_RPAin" 17 "Req_Quit_Recover_Interrupt_Times_Overflow_RPAin" 18 "Req_Quit_D/R_Times_Overflow_RPAin" 19 "Req_Quit_Control_Speed_Over_Limit_RPAin" 20 "Req_Quit_Path_Planning_Abnormal_RPAin" 21 "APP_Quit_RPAIn" 22 "Req_Quit_Slope_Out_Of_limit_RPAin" 23 "Req_Quit_ADAS_Function_Active_RPAin" 24 "Req_Quit_Parking_Total_Time_Out_RPAmove" 25 "Req_Quit_Slope_Out_Of_limit_RPAmove" 26 "Req_Quit_ADD_System_Fail_RPAin" 27 "Req_Quit_ADD_System_Fail_RPAmove" 28 "Blue_Tooth_Connect_UnStable_Timeout_RPA_In" 30 "Req_Quit_ADAS_Function_Active_RPAmove" 31 "Blue_Tooth_Connect_UnStable_Timeout_RPAmove" 32 "Reserved_5" 33 "Req_Quit_Driver_leave_Phone_RPA_Contro_lPage_Time_Out_RPAin" 34 "APP_Quit_RPAmove" 35 "Req_Driver_Interrupt_RPAin" 36 "Req_Driver_Interrupt_RPAmove" 37 "Req_Quit_Driver_Interrupt_Press_Gas_Pedal_RPAin" 38 "Req_Quit_Driver_Interrupt_Press_Brake_Pedal_RPAin" 39 "Battery_Low_RPAmove" 40 "Req_Quit_Handshake_Fail_RPAmove" 41 "Req_Quit_Total_Distance_overrange_RPAmove" 42 "Req_Quit_Warning_someone_In_car_Time_Out_RPAin" 43 "Req_Quit_Control_Speed_Over_Limit_RPAMove" 44 "Req_Quit_Narrow_Slot_RPAin" 45 "Req_Quit_Timeout_Not_Press_Start_Button_RPAin" 46 "Mechanical_Parking_Garage_Narrow_RPAin" 47 "Req_Quit_Function_off_RPAmove" 48 "Battery_Low_RPAin" 49 "Req_Quit_Driver_Interrupt_Gear_RPAmove" 50 "Reserved_6" 51 "Plannig_Control_Sleep_RPAmove" 52 "Req_Quit_MirrorFold_Fail_RPAmove" 53 "Req_Quit_MirrorFold_Fail_RPAin" 54 "Req_Quit_Obstacle_In_Trajectory_Time_Out_RPAmove" 55 "CounterAbnormal_TimeOut_RPAin" 56 "CounterAbnormal_TimeOut_RPAmove" 57 "CRC_Abnormal_RPAin" 58 "CRC_Abnormal_RPAmove" 59 "FrontLid_Open_TimeOut_RPAin" 60 "RearLid_Open_TimeOut_RPAin" 61 "Req_Quit_OtherReason_RPAin" 62 "Reserved_7" 63 "Reserved_8" ;
VAL_ 516 OutdoorPrkRecoverIndFrmADD 0 "None" 1 "Reserved_1" 2 "Req_Recover_Found_Obstacle_In_Trajectory_RPAmove" 3 "Req_Recover_Found_Obstacle_In_Trajectory_RPAin" 4 "Reserved_2" 5 "Reserved_3" 6 "Req_Recover_DoorOpen_Driver_RPAin" 7 "Req_Recover_DoorOpen_passenger_RPAin" 8 "Req_Recover_DoorOpen_LeftRear_RPAin" 9 "Req_Recover_DoorOpen_RightRear_RPAin" 10 "Req_Recover_Engine_Front_DoorOpen_RPAin" 11 "Req_Recover_TrunkOpen_RPAin" 12 "Req_Recover_DoorOpen_RPAmove" 13 "Req_Recover_Engine_Front_DoorOpen_RPAmove" 14 "Req_Recover_TrunkOpen_RPAmove" 15 "Reserved_4" 16 "Reserved_5" 17 "Reserved_6" 18 "CounterAbnormal_RPAin" 19 "CounterAbnormal_RPAmove" 20 "Recover_BlueTooth_Connect_UnStable_RPAin" 21 "Recover_BlueTooth_Connect_UnStable_RPAmove" 22 "Reserved_7" 23 "Reserved_8" 24 "Reserved_9" 25 "Reserved_10" 26 "Reserved_11" 27 "Reserved_12" 28 "Reserved_13" 29 "Reserved_14" 30 "Reserved_15" 31 "Lev_Control_Page_RPAin" ;
VAL_ 516 ParkActiveRearSpoilerReqFrmADD 0 "NoRequest" 1 "Request_Close" 2 "Request_OpenP1" 3 "Request_OpenP2" 4 "Request_OpenP3" 5 "Reserved_1" 6 "Reserved_2" 7 "Reserved_3" ;
VAL_ 516 ParkAtmLiReqFrmADD 0 "NoRequest" 1 "Request_Around" 2 "Request_Red" ;
VAL_ 516 ParkBackMirrorUnfoldReqFrmADD 0 "NoRequest" 1 "Request_Unfold" 2 "Request_Fold" ;
VAL_ 516 ParkCornrLiReqFrmADD 0 "NoRequest" 1 "Request_CornerLightOn" 2 "Reserved" 3 "Reserved" ;
VAL_ 516 ParkDoorLockReqFrmADD 0 "NoRequest" 1 "Request_Unlock" 2 "Request_lock" ;
VAL_ 516 ParkingPushFrmADD 0 "No_Request" 1 "RPA_Park_in" 2 "RPA_Park_out" 3 "RPA_Move" 4 "Reserved" 5 "Reserved" 6 "Reserved" 7 "Reserved" ;
VAL_ 516 ParkLoBeamReqFrmADD 0 "NoRequest" 1 "Request" ;
VAL_ 516 ParkMdlStsFrmADD 0 "NoRequest" 1 "DrivingModel_1" 2 "DrivingModel_2" 3 "DrivingMode_3" 4 "DrivingMode_4" ;
VAL_ 516 ParkTurnLiReqFrmADD 0 "NoRequest" 1 "Leftturnrequest" 2 "Rightturnrequest" 3 "hazardlightrequest" ;
VAL_ 516 ParkWindowReqFrmADD 0 "NoRequest" 1 "Request" ;
VAL_ 516 PASBuzzerWarnMuteIndFrmADD 0 "None" 1 "Mute_info" ;
VAL_ 516 PrkgHornReqFrmADD 0 "No_request" 1 "Request" ;
VAL_ 516 RPAAvailableFrmADD 0 "RPA_available" 1 "RPA_not_available" ;
VAL_ 516 RPADriverOperateIndFrmADD 0 "None" 1 "Reserved_1" 2 "Reserved_2" 3 "Reserved_3" 4 "Reserved_4（active勿用）" 5 "Req_Close_Door_Driver_Parkout" 6 "Req_Close_Door_passenger_Parkout" 7 "Req_Close_Door_LeftRear_RPAParkout" 8 "Req_Close_Door_RightRear_RPAParkout" 9 "Req_Close_Engine_Front_Door_RPAParkout" 10 "Req_Close_Trunk_RPAParkout" 11 "Req_Warning_someone_In_car_RPAParkout" 12 "Searching_Lev_Control_Page_RPAParkout" 13 "Blue_Tooth_Connect_UnStable_RPAParkout" 14 "Reserved_5" 15 "Reserved_6" ;
VAL_ 516 RPAOperateToastFrmADD 0 "None" 1 "Act_More_Trajectory_Mode_RPAin" 2 "Req_Rearview_Mirrors_are_folding_RPAin" 3 "Req_Rearview_Mirrors_are_folding_RPAmove" 4 "Req_RearSpoiler_Closing" 5 "Reserved_1" 6 "Reserved_2" 7 "Reserved_3" 8 "Reserved_4" 9 "Reserved_5" 10 "Reserved_6" 11 "Reserved_7" 12 "Reserved_8" 13 "Reserved_9" 14 "Reserved_10" 15 "Reserved_11" ;
VAL_ 516 RPAQuitReasonIndFrmADD 0 "None" 1 "HDCActvRPAin" 2 "HDCActvRPAMove" 3 "OffroadActvRPAin" 4 "OffroadActvRPAMove" 5 "DrgRacModActv_RPAin" 6 "DrgRacModActv_RPAmove" 7 "DrvModActv_RPAin" 8 "DrvModActv_RPAmove" 9 "DoorOpenTimeOut_RPAout" 10 "FrontLidOpenTimeOut_RPAout" 11 "RearLidOpenTimeOut_Parkout" 12 "Warning_someoneIncarTimeOut_RPAout" 13 "RescueModActv_RPAin" 14 "RescueModActv_RPAmove" 15 "TimeoutNotPressStartButton_RPAout" 16 "WashModActv_RPAin" 17 "WashModActv_RPAmove" 18 "LnchPlusActv_RPAin" 19 "LnchPlusActv_RPAmove" 20 "BatModActv_RPAin" 21 "BatModActv_RPAmove" 22 "SnowModActv_RPAin" 23 "SnowModActv_RPAmove" 24 "BattLow_RPAout" 25 "Blue_Tooth_UnStable_Timeout_RPAout" 26 "APP_RPAout" 27 "ExtremeEcoMode_RPAmove" 28 "JackModActv_RPAin" 29 "JackModActv_RPAmove" 30 "Charg_RPAin" 31 "Charg_RPAmove" 32 "LowPwrMod_RPAout" 33 "ExtremeEcoMode_RPAout" 34 "Charg_RPAout" 35 "ADAS_FcnActvRPAout" 36 "SlopeOutOfLimit_RPAout" 37 "SVSFrontBlkd_RPAout" 38 "SVSRearBlkd_RPAout" 39 "SVSLeftBlkd_RPAout" 40 "SVSRightBlkd_RPAout" 41 "LowPwrMod_RPAmove" 42 "PrivacyMod_RPAin" 43 "PrivacyMod_RPAmove" 44 "ExtmPfmncMod_RPAin" 45 "ExtmPfmncMod_RPAmove" 46 "PrivacyMod_RPAout" 47 "RescueModActv_RPAout" 48 "WashModActv_RPAout" 49 "SVSFrontBlkd_RPAmove" 50 "JackModActv_RPAout" 51 "SVSRearBlkd_RPAmove" 52 "LnchPlusActv_RPAout" 53 "SVSLeftBlkd_RPAmove" 54 "SnowModActv_RPAout" 55 "SVSRightBlkd_RPAmove" 56 "ExtmPfmncMod_RPAout" 57 "BatModActv_RPAout" 58 "DriftModActv_RPAout" 59 "ESCoff_RPAout" 60 "DriftModActv_RPAin" 61 "DriftModActv_RPAmove" 62 "ESCoff_RPAin" 63 "ESCoff_RPAmove" 64 "leavCntrl_PageTimeOut_RPAout" 65 "HDCActvRPAout" 66 "OffroadActvRPAout" 67 "DrvrIntrpt_PressGasPedal_RPAmove" 68 "DrvrIntrpt_PressBrakePedal_RPAmove" 69 "DrgRacModActv_RPAout" 70 "DrvModActv_RPAout" 71 "OtherReason_RPAout" 72 "RC_Not_Available_RPAmove" 73 "RearSpoilerCloseFailed" 74 "System_Failr_RPAout" 75 "HandShakeFail_RPAout" 76 "Drvr_IntrptGear_RPAout" 77 "Drvr_Intrpt_SteerWheel_RPAout" 78 "Drvr_IntrptPressGasPedl_RPAout" 79 "Drvr_IntrptPressBrkPedl_RPAout" 80 "ParkinTotalTimeOut_RPAout" 81 "ObstclinTrajctryTimeOut_RPAout" 82 "CunterAbnormlTimeOut_RPAout" 83 "CRCAbnormal_RPAout" 84 "DrvrIntrpt_RPAout" 85 "CntrlSpeedOverLimit_RPAout" 86 "PathPlanAbnorml_RPAout" 87 "RecovrIntrpt_Times_Overflow_RPAmove" 88 "D/ROverflow_RPAout" 89 "Driver_leavCntrlPage_RPAmove" 90 "resrv1" 91 "resrv2" 92 "resrv3" 93 "resrv4" 94 "resrv5" 95 "resrv6" 96 "resrv7" 97 "resrv8" 98 "resrv9" 99 "resrv10" 100 "resrv11" 101 "resrv12" 102 "resrv13" 103 "resrv14" 104 "resrv15" 105 "resrv16" 106 "resrv17" 107 "resrv18" 108 "resrv19" 109 "resrv20" 110 "resrv21" 111 "resrv22" 112 "resrv23" 113 "resrv24" 114 "resrv25" 115 "resrv26" 116 "resrv27" 117 "resrv28" 118 "resrv29" 119 "resrv30" 120 "resrv31" 121 "resrv32" 122 "resrv33" 123 "resrv34" 124 "resrv35" 125 "resrv36" 126 "resrv37" 127 "resrv38" ;
VAL_ 516 RPAUnableToActiveIndFrmADD 0 "None" 1 "HDC_Active_RPAMove" 2 "Game_Mode_RPAMove" 3 "Limd_Warn_RPAMove" 4 "Carmod_Not_Allowed_RPAMove" 5 "ESC_OFF_RPAmove" 6 "lvl_Adjusting_RPAMove" 7 "Charhing_RPAMove" 8 "Wash_Mode_RPAMove" 9 "Off_Road_Active_RPAMove" 10 "P_Speed_Not_Zero_RPAmove" 11 "Drg_Rac_Mod_Active_RPAmove" 12 "Parking_Active_RPAmove" 13 "Drv_Mod_Active_RPAMove" 14 "Reserved_1" 15 "Reserved_2" ;
VAL_ 516 WeatherStsFrmADD 0 "Unknown" 1 "GoodWeather" 2 "HeavyRain" 3 "HeavySnow" ;
VAL_ 519 BndryValidity1FrmADD 0 "Invalid" 1 "Valid" ;
VAL_ 519 BndryValidity2FrmADD 0 "Invalid" 1 "Valid" ;
VAL_ 519 BndryValidity3FrmADD 0 "Invalid" 1 "Valid" ;
VAL_ 519 BndryValidity4FrmADD 0 "Invalid" 1 "Valid" ;
VAL_ 519 BndryValidity5FrmADD 0 "Invalid" 1 "Valid" ;
VAL_ 519 EnvIllumFrmADD 0 "LitEnvironment" 1 "DarkNight" 2 "Reserved1" 3 "Reserved2" ;
VAL_ 519 TooManyBndryFlagFrmADD 0 "InActive" 1 "Active" ;
VAL_ 519 TooManyVehFlagFrmADD 0 "InActive" 1 "Active" ;
VAL_ 519 TrafSignValidity1FrmADD 0 "Invalid" 1 "Valid" ;
VAL_ 519 TrafSignValidity2FrmADD 0 "Invalid" 1 "Valid" ;
VAL_ 519 VehObjDir1FrmADD 0 "AheadObject" 1 "IncomingObject" ;
VAL_ 519 VehObjDir2FrmADD 0 "AheadObject" 1 "IncomingObject" ;
VAL_ 519 VehObjDir3FrmADD 0 "AheadObject" 1 "IncomingObject" ;
VAL_ 519 VehObjDir4FrmADD 0 "AheadObject" 1 "IncomingObject" ;
VAL_ 519 VehObjDir5FrmADD 0 "AheadObject" 1 "IncomingObject" ;
VAL_ 519 VehObjDir6FrmADD 0 "AheadObject" 1 "IncomingObject" ;
VAL_ 519 VehObjDir7FrmADD 0 "AheadObject" 1 "IncomingObject" ;
VAL_ 519 VehObjDir8FrmADD 0 "AheadObject" 1 "IncomingObject" ;
VAL_ 519 VehObjType1FrmADD 0 "Unknown" 1 "fourwheelVehicle" 2 "MotorcycleOrBicycle" 3 "Reserved" ;
VAL_ 519 VehObjType2FrmADD 0 "Unknown" 1 "fourwheelVehicle" 2 "MotorcycleOrBicycle" 3 "Reserved" ;
VAL_ 519 VehObjType3FrmADD 0 "Unknown" 1 "fourwheelVehicle" 2 "MotorcycleOrBicycle" 3 "Reserved" ;
VAL_ 519 VehObjType4FrmADD 0 "Unknown" 1 "fourwheelVehicle" 2 "MotorcycleOrBicycle" 3 "Reserved" ;
VAL_ 519 VehObjType5FrmADD 0 "Unknown" 1 "fourwheelVehicle" 2 "MotorcycleOrBicycle" 3 "Reserved" ;
VAL_ 519 VehObjType6FrmADD 0 "Unknown" 1 "fourwheelVehicle" 2 "MotorcycleOrBicycle" 3 "Reserved" ;
VAL_ 519 VehObjType7FrmADD 0 "Unknown" 1 "fourwheelVehicle" 2 "MotorcycleOrBicycle" 3 "Reserved" ;
VAL_ 519 VehObjType8FrmADD 0 "Unknown" 1 "fourwheelVehicle" 2 "MotorcycleOrBicycle" 3 "Reserved" ;
VAL_ 519 VehObjValidity1FrmADD 0 "Invalid" 1 "Valid" ;
VAL_ 519 VehObjValidity2FrmADD 0 "Invalid" 1 "Valid" ;
VAL_ 519 VehObjValidity3FrmADD 0 "Invalid" 1 "Valid" ;
VAL_ 519 VehObjValidity4FrmADD 0 "Invalid" 1 "Valid" ;
VAL_ 519 VehObjValidity5FrmADD 0 "Invalid" 1 "Valid" ;
VAL_ 519 VehObjValidity6FrmADD 0 "Invalid" 1 "Valid" ;
VAL_ 519 VehObjValidity7FrmADD 0 "Invalid" 1 "Valid" ;
VAL_ 519 VehObjValidity8FrmADD 0 "Invalid" 1 "Valid" ;
VAL_ 661 ADSRCTBBrkReqFrmADD 0 "no_request" 1 "request" ;
VAL_ 661 BmpTrk1ConfFrmADD 127 "invalid" ;
SIG_GROUP_ 379 ParkGearReqSigGrp 1 : ParkGearReqEnaFrmADD ParkGearReqFrmADD ParkGearReqSigGrpChks ParkGearReqSigGrpCntr RPAHVOnReqFrmADD RPAPrkinRecdFrmADD;
SIG_GROUP_ 399 HPPAVPSteerReqBkpSigGrp 1 : HPPAVPRecoverIndCtrlBkp HPPAVPSteerReqBkpSigGrpChks HPPAVPSteerReqBkpSigGrpCntr HPPAVPSteerWhlAglReqValBkp HPPAVPSteerWhlCtrlReqStsBkp;
SIG_GROUP_ 493 ParkCtrlAirSuspSigGrp 1 : ParkAirSuspReqFrmADD ParkCtrlAirSuspSigGrpChks ParkCtrlAirSuspSigGrpCntr;
SIG_GROUP_ 512 ADSFctStsSigGrp 1 : ADDBSDLCAStsFrmADD ADSAEBStsFrmADD ADSAEBTarDirFrmADD ADSDOWStsFrmADD ADSELKStsFrmADD ADSESSStsFrmADD ADSFctStsSigGrpChks ADSFctStsSigGrpCntr ADSFCWStsFrmADD ADSLDPStsFrmADD ADSLDWStsFrmADD ADSRCTAStsFrmADD ADSRCTBStsFrmADD ADSRCWStsFrmADD;
SIG_GROUP_ 512 ADSGearReqSigGrp 1 : ADSGearReqSigGrpChks ADSGearReqSigGrpCntr DrvGearReqFrmADD DrvGearReqVldFrmADD;
SIG_GROUP_ 512 ADSWarnRemd2SigGrp 1 : ADSLiReqFrmADD AutoDrvLaneChgStsFrmADD DrvHUDDspFrmADD DrvLaneChgStsFrmADD DrvNOAExtLgtDstFrmADD DrvNOAQutLgtDstFrmADD DrvPltSysStsFrmADD DrvrSeldDstLvlFrmADD DrvTurnLiReqFrmADD IndcrCancelReqFrmADD NOASysStsFrmADD UserFbReqFrmADD;
SIG_GROUP_ 512 ADSWarnSigGrp 1 : ADSAEBWarnReqFrmADD ADSBSDLCAAudioWarnReqFrmADD ADSBSDLCAWarnReqLeFrmADD ADSBSDLCAWarnReqRiFrmADD ADSBSDLightWarningLeReqFrmADD ADSBSDLightWarningRiReqFrmADD ADSDOWWarnReqFrLeFrmADD ADSDOWWarnReqFrRiFrmADD ADSDOWWarnReqReLeFrmADD ADSDOWWarnReqReRiFrmADD ADSESSWarnReqFrmADD ADSFCWReqFrmADD ADSLDPHandOffExitFrmADD ADSLDPHandOffWarningFrmADD ADSLDPWarnReqLeFrmADD ADSLDPWarnReqRiFrmADD ADSLDWWarnLeReqFrmADD ADSLDWWarnRiReqFrmADD ADSRCTAWarnReqLeFrmADD ADSRCTAWarnReqRiFrmADD ADSRCTBWarnReqLeFrmADD ADSRCTBWarnReqRiFrmADD ADSRCWWarnReqFrmADD ADSVcCtrlArbFrmADD ADSWarnSigGrpChks ADSWarnSigGrpCntr DrvAtmLiReqFrmADD DrvSysWarnFrmADD TSASignQlyFrmADD TSASignTypeFrmADD TSASpdLimitFrmADD TSASpdLimitUnitFrmADD;
SIG_GROUP_ 512 ADSwtStsSigGrp2 1 : AdsLearnSwtStsFrmADD AdsLearnSwtUnavlRsnFrmADD AdsModSwtStsFrmADD AdsNOAOddSwtStsFrmADD AdsNOAOddSwtUnavlRsnFrmADD AdsTrfcLiCtrlSwtStsFrmADD AdsVehDetourSwtStsFrmADD ADSwtStsSigGrp2Chks ADSwtStsSigGrp2Cntr;
SIG_GROUP_ 512 AEBtoIDPSigGrp 1 : AEBTarObjClassFrmADD AEBTarObjTTIFrmADD AEBtoIDPFrmADDChks AEBtoIDPFrmADDCntr;
SIG_GROUP_ 512 AVMCamVideoChainStsGrp 1 : AVMCamVideoChainSts AVMCamVideoChainStsChks AVMCamVideoChainStsCntr;
SIG_GROUP_ 513 AVPHPPStatusSigGrp 1 : ADSAPPUnableOpenRsnFrmADD ADSAVPStsFrmADD ADSHPPStsFrmADD AVPHPPStatusSigGrpChks AVPHPPStatusSigGrpCntr HPPActiveSubStsFrmADD HPPAlrtWarnFrmADD HPPDriverOperateDialogFrmADD HPPDriverOperateInd2FrmADD HPPDriverOperateIndFrmADD HPPInfotipFrmADD HPPLearnSubStsFrmADD HPPQuitIndFrmADD HPPRecoverIndFrmADD HPPRouteInd2FrmADD HPPRouteIndFrmADD HPPUnableToActiveIndFrmADD;
SIG_GROUP_ 513 DVRStsSigGrp 1 : F120DVRStsFrmADD F30DVRStsFrmADD ReDVRStsFrmADD SLFDVRStsFrmADD SLRDVRStsFrmADD SRFDVRStsFrmADD SRRDVRStsFrmADD;
SIG_GROUP_ 513 HPPToSRSigGrp 1 : HPPBakMapDfltParkSlotDispFrmADD HPPPlayBackPushFrmADD HPPRecoverButtonStsFrmADD HPPRouteManageStsFrmADD HPPToSRSigGrpChks HPPToSRSigGrpCntr HPPVehInParkSlotFrmADD;
SIG_GROUP_ 513 ParkIcnStsSigGrp 1 : APAIcnDispStsFrmADD AVPIcnDispStsFrmADD HPPIcnDispStsFrmADD ParkIcnStsSigGrpChks ParkIcnStsSigGrpCntr PrkSteerWhlBtnLi;
SIG_GROUP_ 513 ParkVCstatusSigGrp 1 : APAVcFbFrmADD APAVcQuitAvlFrmADD APAVcStsFrmADD AVMOpnReqFrmADD HPPLrnVcFbFrmADD ParkVCstatusSigGrpChks ParkVCstatusSigGrpCntr ParkVicShdFrmADD;
SIG_GROUP_ 513 SnmDetResSigGrp 1 : SnmDetInfoFrmADD SnmDetResFrmADD SnmF120CamDetResFrmADD SnmReCamDetResFrmADD SnmSLFCamDetResFrmADD SnmSLRCamDetResFrmADD SnmSRFCamDetResFrmADD SnmSRRCamDetResFrmADD;
SIG_GROUP_ 516 APARPAstatusSigGrp 1 : APAAlrtWarnFrmADD APARPAActiveSubFunFrmADD APARPADriverOperateInd2FrmADD APARPADriverOperateIndFrmADD APARPAQuitReasonIndFrmADD APARPARecoverIndFrmADD APARPAstatusFrmADD APARPAstatusSigGrpChks APARPAstatusSigGrpCntr APARPAUnableToActiveIndFrmADD ParkProgressSigReDistFrmADD PRAMoveSigReDistFrmADD;
SIG_GROUP_ 516 ParkLightReqSigGrp 1 : AVPCharLidCtrlFrmADD ParkAtmLiReqFrmADD ParkBackMirrorUnfoldReqFrmADD ParkDoorLockReqFrmADD ParkLightReqSigGrpChks ParkLightReqSigGrpCntr ParkLoBeamReqFrmADD ParkTurnLiReqFrmADD ParkWindowReqFrmADD PrkgHornReqFrmADD RPAAvailableFrmADD;
SIG_GROUP_ 661 ADSRCTBBrkSigGrp 1 : ADSRCTBBrkReqFrmADD ADSRCTBBrkSigGrpChks ADSRCTBBrkSigGrpCntr ADSRCTBTarDecelFrmADD;
